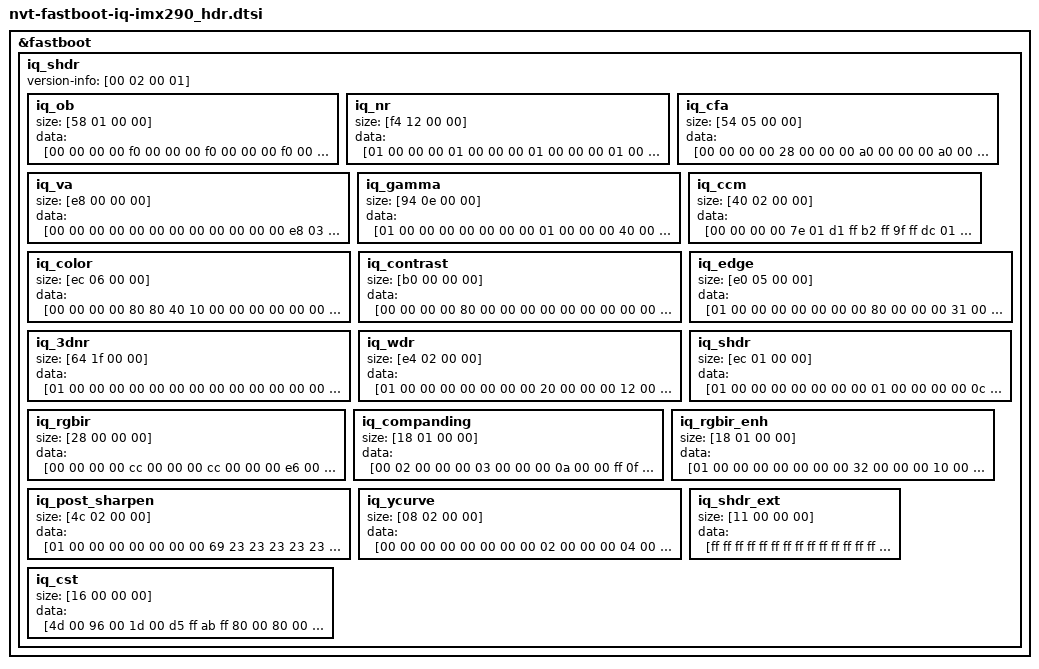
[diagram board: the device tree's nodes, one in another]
/*
 * Novatek Ltd. NVT9856x ISP part of dts
 */

&fastboot {
	iq_shdr {
		version-info = [00 02 00 01];
		iq_ob {
			size = [58 01 00 00];
			data = [00 00 00 00 f0 00 00 00 f0 00 00 00 f0 00 00 00 f0 00 00 00 f0 00 00 00 f0 00 00 00 f0 00 00 00 f0 00 00 00 f0 00 00 00 f0 00 00 00 f0 00 00 00 f0 00 00 00 f0 00 00 00 f0 00 00 00 f0 00 00 00 f0 00 00 00 f0 00 00 00 f0 00 00 00 f0 00 00 00 f0 00 00 00 f0 00 00 00 f0 00 00 00 f0 00 00 00 f0 00 00 00 f0 00 00 00 f0 00 00 00 f0 00 00 00 f0 00 00 00 f0 00 00 00 f0 00 00 00 f0 00 00 00 f0 00 00 00 f0 00 00 00 f0 00 00 00 f0 00 00 00 f0 00 00 00 f0 00 00 00 f0 00 00 00 f0 00 00 00 f0 00 00 00 f0 00 00 00 f0 00 00 00 f0 00 00 00 f0 00 00 00 f0 00 00 00 f0 00 00 00 f0 00 00 00 f0 00 00 00 f0 00 00 00 f0 00 00 00 f0 00 00 00 f0 00 00 00 f0 00 00 00 f0 00 00 00 f0 00 00 00 f0 00 00 00 f0 00 00 00 f0 00 00 00 f0 00 00 00 f0 00 00 00 f0 00 00 00 f0 00 00 00 f0 00 00 00 f0 00 00 00 f0 00 00 00 f0 00 00 00 f0 00 00 00 f0 00 00 00 f0 00 00 00 f0 00 00 00 f0 00 00 00 f0 00 00 00 f0 00 00 00 f0 00 00 00 f0 00 00 00 f0 00 00 00 f0 00 00 00 f0 00 00 00 f0 00 00 00 f0 00 00 00 f0 00 00 00 f0 00 00 00 f0 00 00 00 f0 00 00 00 f0 00 00 00];
		};
		iq_nr {
			size = [f4 12 00 00];
			data = [01 00 00 00 01 00 00 00 01 00 00 00 01 00 00 00 01 00 00 00 00 00 00 00 00 01 ff 00 00 00 00 00 00 00 00 00 ff 0f 00 00 ff 0f 00 00 ff 0f 00 00 ff 0f 00 00 ff 0f 00 00 ff 0f 00 00 ff 0f 00 00 ff 0f 00 00 ff 0f 00 00 ff 0f 00 00 00 01 80 00 00 00 00 00 00 00 00 00 00 00 00 00 00 00 00 00 00 00 00 00 00 00 00 00 00 00 00 00 00 00 00 00 00 00 00 00 00 00 00 00 00 00 00 00 00 00 00 00 00 00 00 00 00 00 00 00 00 00 00 00 00 00 00 00 00 00 00 00 00 00 00 00 00 00 00 00 00 00 00 00 00 00 00 00 00 00 00 00 00 00 00 00 00 00 00 00 00 00 00 00 00 00 00 00 00 00 00 00 00 00 00 00 00 00 00 00 00 00 00 00 00 00 00 00 00 00 00 00 00 00 00 00 00 00 00 00 00 00 00 00 00 00 00 00 00 00 00 00 00 00 00 00 00 00 00 00 00 00 00 00 00 00 00 00 00 00 00 00 00 00 00 00 00 00 00 00 00 00 00 00 00 00 00 00 00 00 00 00 00 00 00 00 80 00 00 00 00 00 00 00 00 00 00 00 00 00 00 00 00 00 00 00 00 00 00 00 00 00 00 00 02 00 00 00 02 00 00 00 00 01 ff 00 00 00 00 00 00 00 00 00 20 00 00 00 6c 07 00 00 3f 0c 00 00 ff 0f 00 00 ff 0f 00 00 20 00 00 00 6c 07 00 00 3f 0c 00 00 ff 0f 00 00 ff 0f 00 00 02 00 80 00 00 00 00 00 00 00 00 00 00 00 00 00 00 00 00 00 00 00 00 00 00 00 00 00 00 00 00 00 00 00 00 00 00 00 00 00 00 00 00 00 00 00 00 00 00 00 00 00 00 00 00 00 00 00 00 00 00 00 00 00 00 00 00 00 00 00 00 00 00 00 00 00 00 00 00 00 00 00 00 00 00 00 00 00 00 00 00 00 00 00 00 00 00 00 00 00 00 00 00 00 00 00 00 00 00 00 00 00 00 00 00 00 00 00 00 00 00 00 00 00 00 00 00 00 00 00 00 00 00 00 00 00 00 00 00 00 00 00 00 00 00 00 00 00 00 00 00 00 00 00 00 00 00 00 00 00 00 00 00 00 00 00 00 00 00 00 00 00 00 00 00 00 00 00 00 00 00 00 00 00 00 00 00 00 00 00 00 00 20 00 00 00 40 00 00 00 10 00 00 00 10 00 00 00 10 00 00 00 10 00 00 00 00 00 00 00 00 00 00 00 00 00 00 00 00 00 00 00 00 01 ff 00 00 00 00 00 00 00 00 00 20 00 00 00 6c 07 00 00 3f 0c 00 00 ff 0f 00 00 ff 0f 00 00 20 00 00 00 6c 07 00 00 3f 0c 00 00 ff 0f 00 00 ff 0f 00 00 02 00 80 00 00 00 00 00 00 00 00 00 00 00 00 00 01 00 00 00 01 00 00 00 01 00 00 00 00 00 00 00 01 00 00 00 01 00 00 00 02 00 00 00 02 00 00 00 02 00 00 00 02 00 00 00 03 00 00 00 03 00 00 00 03 00 00 00 03 00 00 00 03 00 00 00 04 00 00 00 04 00 00 00 04 00 00 00 04 00 00 00 04 00 00 00 00 00 00 00 01 00 00 00 02 00 00 00 03 00 00 00 03 00 00 00 04 00 00 00 00 00 00 00 01 00 00 00 01 00 00 00 02 00 00 00 02 00 00 00 02 00 00 00 02 00 00 00 03 00 00 00 03 00 00 00 03 00 00 00 03 00 00 00 03 00 00 00 04 00 00 00 04 00 00 00 04 00 00 00 04 00 00 00 04 00 00 00 00 00 00 00 20 00 00 00 40 00 00 00 10 00 00 00 10 00 00 00 10 00 00 00 10 00 00 00 00 00 00 00 00 00 00 00 00 00 00 00 00 00 00 00 00 01 ff 00 00 00 00 00 00 00 00 00 20 00 00 00 bb 06 00 00 1b 0b 00 00 ff 0f 00 00 ff 0f 00 00 20 00 00 00 bb 06 00 00 1b 0b 00 00 ff 0f 00 00 ff 0f 00 00 02 00 80 00 00 00 00 00 01 00 00 00 01 00 00 00 02 00 00 00 02 00 00 00 03 00 00 00 00 00 00 00 02 00 00 00 03 00 00 00 04 00 00 00 04 00 00 00 05 00 00 00 05 00 00 00 06 00 00 00 06 00 00 00 07 00 00 00 07 00 00 00 07 00 00 00 08 00 00 00 08 00 00 00 08 00 00 00 09 00 00 00 09 00 00 00 00 00 00 00 03 00 00 00 04 00 00 00 06 00 00 00 07 00 00 00 09 00 00 00 00 00 00 00 02 00 00 00 03 00 00 00 04 00 00 00 04 00 00 00 05 00 00 00 05 00 00 00 06 00 00 00 06 00 00 00 07 00 00 00 07 00 00 00 07 00 00 00 08 00 00 00 08 00 00 00 08 00 00 00 09 00 00 00 09 00 00 00 00 00 00 00 20 00 00 00 40 00 00 00 10 00 00 00 10 00 00 00 10 00 00 00 10 00 00 00 00 00 00 00 00 00 00 00 00 00 00 00 00 00 00 00 00 01 ff 00 00 00 00 00 00 00 00 00 20 00 00 00 44 06 00 00 57 0a 00 00 fe 0e 00 00 ff 0f 00 00 20 00 00 00 44 06 00 00 57 0a 00 00 fe 0e 00 00 ff 0f 00 00 02 00 80 00 00 00 00 00 01 00 00 00 02 00 00 00 03 00 00 00 03 00 00 00 04 00 00 00 00 00 00 00 03 00 00 00 04 00 00 00 05 00 00 00 06 00 00 00 07 00 00 00 07 00 00 00 08 00 00 00 09 00 00 00 09 00 00 00 0a 00 00 00 0a 00 00 00 0b 00 00 00 0b 00 00 00 0b 00 00 00 0c 00 00 00 0c 00 00 00 00 00 00 00 05 00 00 00 07 00 00 00 09 00 00 00 0a 00 00 00 0e 00 00 00 00 00 00 00 03 00 00 00 04 00 00 00 05 00 00 00 06 00 00 00 07 00 00 00 07 00 00 00 08 00 00 00 09 00 00 00 09 00 00 00 0a 00 00 00 0a 00 00 00 0b 00 00 00 0b 00 00 00 0b 00 00 00 0c 00 00 00 0c 00 00 00 00 00 00 00 20 00 00 00 40 00 00 00 10 00 00 00 10 00 00 00 10 00 00 00 10 00 00 00 00 00 00 00 02 00 00 00 00 00 00 00 00 00 00 00 00 01 ff 00 00 00 00 00 00 00 00 00 20 00 00 00 cd 05 00 00 92 09 00 00 e1 0d 00 00 ff 0f 00 00 20 00 00 00 cd 05 00 00 92 09 00 00 e1 0d 00 00 ff 0f 00 00 06 00 80 00 00 00 00 00 02 00 00 00 03 00 00 00 04 00 00 00 04 00 00 00 06 00 00 00 00 00 00 00 04 00 00 00 05 00 00 00 06 00 00 00 08 00 00 00 08 00 00 00 09 00 00 00 0a 00 00 00 0b 00 00 00 0c 00 00 00 0c 00 00 00 0d 00 00 00 0d 00 00 00 0e 00 00 00 0e 00 00 00 0f 00 00 00 10 00 00 00 00 00 00 00 07 00 00 00 09 00 00 00 0c 00 00 00 0e 00 00 00 13 00 00 00 00 00 00 00 04 00 00 00 05 00 00 00 06 00 00 00 08 00 00 00 08 00 00 00 09 00 00 00 0a 00 00 00 0b 00 00 00 0c 00 00 00 0c 00 00 00 0d 00 00 00 0d 00 00 00 0e 00 00 00 0e 00 00 00 0f 00 00 00 10 00 00 00 00 00 00 00 20 00 00 00 40 00 00 00 10 00 00 00 10 00 00 00 10 00 00 00 10 00 00 00 00 00 00 00 04 00 00 00 00 00 00 00 00 00 00 00 00 01 ff 00 00 00 00 00 00 00 00 00 20 00 00 00 56 05 00 00 ce 08 00 00 c4 0c 00 00 ff 0f 00 00 20 00 00 00 56 05 00 00 ce 08 00 00 c4 0c 00 00 ff 0f 00 00 08 00 80 00 00 00 00 00 03 00 00 00 05 00 00 00 06 00 00 00 07 00 00 00 0a 00 00 00 00 00 00 00 06 00 00 00 08 00 00 00 0a 00 00 00 0c 00 00 00 0d 00 00 00 0e 00 00 00 0f 00 00 00 10 00 00 00 12 00 00 00 12 00 00 00 13 00 00 00 14 00 00 00 15 00 00 00 16 00 00 00 17 00 00 00 18 00 00 00 00 00 00 00 0b 00 00 00 10 00 00 00 13 00 00 00 16 00 00 00 20 00 00 00 00 00 00 00 06 00 00 00 08 00 00 00 0a 00 00 00 0c 00 00 00 0d 00 00 00 0e 00 00 00 0f 00 00 00 10 00 00 00 12 00 00 00 12 00 00 00 13 00 00 00 14 00 00 00 15 00 00 00 16 00 00 00 17 00 00 00 18 00 00 00 00 00 00 00 20 00 00 00 40 00 00 00 10 00 00 00 10 00 00 00 10 00 00 00 10 00 00 00 00 00 00 00 06 00 00 00 00 00 00 00 00 00 00 00 00 01 ff 00 00 00 00 00 00 00 00 00 20 00 00 00 df 04 00 00 0a 08 00 00 a8 0b 00 00 ff 0f 00 00 20 00 00 00 df 04 00 00 0a 08 00 00 a8 0b 00 00 ff 0f 00 00 0f 00 80 00 00 00 00 00 05 00 00 00 07 00 00 00 09 00 00 00 0a 00 00 00 0e 00 00 00 00 00 00 00 09 00 00 00 0d 00 00 00 0f 00 00 00 12 00 00 00 14 00 00 00 16 00 00 00 18 00 00 00 1a 00 00 00 1b 00 00 00 1d 00 00 00 1e 00 00 00 1f 00 00 00 21 00 00 00 22 00 00 00 23 00 00 00 24 00 00 00 00 00 00 00 0f 00 00 00 16 00 00 00 1b 00 00 00 1f 00 00 00 2c 00 00 00 00 00 00 00 09 00 00 00 0d 00 00 00 0f 00 00 00 12 00 00 00 14 00 00 00 16 00 00 00 18 00 00 00 1a 00 00 00 1b 00 00 00 1d 00 00 00 1e 00 00 00 1f 00 00 00 21 00 00 00 22 00 00 00 23 00 00 00 24 00 00 00 08 00 00 00 20 00 00 00 40 00 00 00 10 00 00 00 10 00 00 00 10 00 00 00 10 00 00 00 00 00 00 00 08 00 00 00 01 00 00 00 01 00 00 00 00 01 ff 00 00 00 00 00 00 00 00 00 20 00 00 00 68 04 00 00 45 07 00 00 8a 0a 00 00 ff 0f 00 00 20 00 00 00 68 04 00 00 45 07 00 00 8a 0a 00 00 ff 0f 00 00 1e 00 80 00 00 00 00 00 07 00 00 00 0b 00 00 00 0d 00 00 00 0f 00 00 00 16 00 00 00 00 00 00 00 16 00 00 00 1f 00 00 00 26 00 00 00 2c 00 00 00 31 00 00 00 35 00 00 00 3a 00 00 00 3e 00 00 00 42 00 00 00 45 00 00 00 48 00 00 00 4c 00 00 00 4f 00 00 00 52 00 00 00 55 00 00 00 58 00 00 00 00 00 00 00 14 00 00 00 1d 00 00 00 24 00 00 00 29 00 00 00 3b 00 00 00 00 00 00 00 16 00 00 00 1f 00 00 00 26 00 00 00 2c 00 00 00 31 00 00 00 35 00 00 00 3a 00 00 00 3e 00 00 00 42 00 00 00 45 00 00 00 48 00 00 00 4c 00 00 00 4f 00 00 00 52 00 00 00 55 00 00 00 58 00 00 00 0f 00 00 00 20 00 00 00 40 00 00 00 10 00 00 00 14 00 00 00 10 00 00 00 14 00 00 00 04 00 00 00 10 00 00 00 01 00 00 00 02 00 00 00 00 01 ff 00 00 00 00 00 00 00 00 00 20 00 00 00 68 04 00 00 45 07 00 00 8a 0a 00 00 ff 0f 00 00 20 00 00 00 68 04 00 00 45 07 00 00 8a 0a 00 00 ff 0f 00 00 3c 00 80 00 00 00 00 00 08 00 00 00 0c 00 00 00 0e 00 00 00 11 00 00 00 18 00 00 00 00 00 00 00 26 00 00 00 36 00 00 00 42 00 00 00 4c 00 00 00 55 00 00 00 5e 00 00 00 65 00 00 00 6c 00 00 00 73 00 00 00 79 00 00 00 7f 00 00 00 85 00 00 00 8a 00 00 00 8f 00 00 00 94 00 00 00 99 00 00 00 00 00 00 00 19 00 00 00 24 00 00 00 2c 00 00 00 33 00 00 00 48 00 00 00 00 00 00 00 26 00 00 00 36 00 00 00 42 00 00 00 4c 00 00 00 55 00 00 00 5e 00 00 00 65 00 00 00 6c 00 00 00 73 00 00 00 79 00 00 00 7f 00 00 00 85 00 00 00 8a 00 00 00 8f 00 00 00 94 00 00 00 99 00 00 00 0f 00 00 00 20 00 00 00 40 00 00 00 14 00 00 00 18 00 00 00 14 00 00 00 18 00 00 00 04 00 00 00 12 00 00 00 01 00 00 00 02 00 00 00 00 01 ff 00 00 00 00 00 00 00 00 00 20 00 00 00 68 04 00 00 45 07 00 00 8a 0a 00 00 ff 0f 00 00 20 00 00 00 68 04 00 00 45 07 00 00 8a 0a 00 00 ff 0f 00 00 5a 00 80 00 00 00 00 00 0b 00 00 00 10 00 00 00 13 00 00 00 16 00 00 00 20 00 00 00 00 00 00 00 33 00 00 00 48 00 00 00 58 00 00 00 66 00 00 00 72 00 00 00 7d 00 00 00 87 00 00 00 90 00 00 00 99 00 00 00 a1 00 00 00 a9 00 00 00 b1 00 00 00 b8 00 00 00 bf 00 00 00 c6 00 00 00 cc 00 00 00 00 00 00 00 21 00 00 00 2f 00 00 00 3a 00 00 00 43 00 00 00 5e 00 00 00 00 00 00 00 33 00 00 00 48 00 00 00 58 00 00 00 66 00 00 00 72 00 00 00 7d 00 00 00 87 00 00 00 90 00 00 00 99 00 00 00 a1 00 00 00 a9 00 00 00 b1 00 00 00 b8 00 00 00 bf 00 00 00 c6 00 00 00 cc 00 00 00 0f 00 00 00 20 00 00 00 40 00 00 00 18 00 00 00 1c 00 00 00 18 00 00 00 1c 00 00 00 06 00 00 00 14 00 00 00 01 00 00 00 02 00 00 00 00 01 ff 00 00 00 00 00 00 00 00 00 20 00 00 00 68 04 00 00 45 07 00 00 8a 0a 00 00 ff 0f 00 00 20 00 00 00 68 04 00 00 45 07 00 00 8a 0a 00 00 ff 0f 00 00 5a 00 80 00 00 00 00 00 0d 00 00 00 13 00 00 00 17 00 00 00 1b 00 00 00 26 00 00 00 00 00 00 00 15 00 00 00 1d 00 00 00 24 00 00 00 2a 00 00 00 2f 00 00 00 33 00 00 00 38 00 00 00 3b 00 00 00 3f 00 00 00 43 00 00 00 46 00 00 00 49 00 00 00 4c 00 00 00 4f 00 00 00 52 00 00 00 54 00 00 00 00 00 00 00 28 00 00 00 39 00 00 00 46 00 00 00 51 00 00 00 72 00 00 00 00 00 00 00 40 00 00 00 5a 00 00 00 6e 00 00 00 80 00 00 00 8f 00 00 00 9c 00 00 00 a9 00 00 00 b5 00 00 00 c0 00 00 00 ca 00 00 00 d4 00 00 00 dd 00 00 00 e6 00 00 00 ef 00 00 00 f7 00 00 00 00 01 00 00 0f 00 00 00 20 00 00 00 40 00 00 00 1c 00 00 00 20 00 00 00 1c 00 00 00 20 00 00 00 0a 00 00 00 18 00 00 00 01 00 00 00 02 00 00 00 00 01 ff 00 00 00 00 00 00 00 00 00 20 00 00 00 68 04 00 00 45 07 00 00 8a 0a 00 00 ff 0f 00 00 20 00 00 00 68 04 00 00 45 07 00 00 8a 0a 00 00 ff 0f 00 00 5a 00 80 00 00 00 00 00 0d 00 00 00 13 00 00 00 17 00 00 00 1b 00 00 00 26 00 00 00 00 00 00 00 15 00 00 00 1d 00 00 00 24 00 00 00 2a 00 00 00 2f 00 00 00 33 00 00 00 38 00 00 00 3b 00 00 00 3f 00 00 00 43 00 00 00 46 00 00 00 49 00 00 00 4c 00 00 00 4f 00 00 00 52 00 00 00 54 00 00 00 00 00 00 00 28 00 00 00 39 00 00 00 46 00 00 00 51 00 00 00 72 00 00 00 00 00 00 00 40 00 00 00 5a 00 00 00 6e 00 00 00 80 00 00 00 8f 00 00 00 9c 00 00 00 a9 00 00 00 b5 00 00 00 c0 00 00 00 ca 00 00 00 d4 00 00 00 dd 00 00 00 e6 00 00 00 ef 00 00 00 f7 00 00 00 00 01 00 00 0f 00 00 00 20 00 00 00 40 00 00 00 1c 00 00 00 20 00 00 00 1c 00 00 00 20 00 00 00 0a 00 00 00 18 00 00 00 01 00 00 00 02 00 00 00 00 01 ff 00 00 00 00 00 00 00 00 00 20 00 00 00 68 04 00 00 45 07 00 00 8a 0a 00 00 ff 0f 00 00 20 00 00 00 68 04 00 00 45 07 00 00 8a 0a 00 00 ff 0f 00 00 5a 00 80 00 00 00 00 00 0d 00 00 00 13 00 00 00 17 00 00 00 1b 00 00 00 26 00 00 00 00 00 00 00 15 00 00 00 1d 00 00 00 24 00 00 00 2a 00 00 00 2f 00 00 00 33 00 00 00 38 00 00 00 3b 00 00 00 3f 00 00 00 43 00 00 00 46 00 00 00 49 00 00 00 4c 00 00 00 4f 00 00 00 52 00 00 00 54 00 00 00 00 00 00 00 28 00 00 00 39 00 00 00 46 00 00 00 51 00 00 00 72 00 00 00 00 00 00 00 40 00 00 00 5a 00 00 00 6e 00 00 00 80 00 00 00 8f 00 00 00 9c 00 00 00 a9 00 00 00 b5 00 00 00 c0 00 00 00 ca 00 00 00 d4 00 00 00 dd 00 00 00 e6 00 00 00 ef 00 00 00 f7 00 00 00 00 01 00 00 0f 00 00 00 20 00 00 00 40 00 00 00 1c 00 00 00 20 00 00 00 1c 00 00 00 20 00 00 00 0a 00 00 00 18 00 00 00 01 00 00 00 02 00 00 00 00 01 ff 00 00 00 00 00 00 00 00 00 20 00 00 00 68 04 00 00 45 07 00 00 8a 0a 00 00 ff 0f 00 00 20 00 00 00 68 04 00 00 45 07 00 00 8a 0a 00 00 ff 0f 00 00 5a 00 80 00 00 00 00 00 0d 00 00 00 13 00 00 00 17 00 00 00 1b 00 00 00 26 00 00 00 00 00 00 00 15 00 00 00 1d 00 00 00 24 00 00 00 2a 00 00 00 2f 00 00 00 33 00 00 00 38 00 00 00 3b 00 00 00 3f 00 00 00 43 00 00 00 46 00 00 00 49 00 00 00 4c 00 00 00 4f 00 00 00 52 00 00 00 54 00 00 00 00 00 00 00 28 00 00 00 39 00 00 00 46 00 00 00 51 00 00 00 72 00 00 00 00 00 00 00 40 00 00 00 5a 00 00 00 6e 00 00 00 80 00 00 00 8f 00 00 00 9c 00 00 00 a9 00 00 00 b5 00 00 00 c0 00 00 00 ca 00 00 00 d4 00 00 00 dd 00 00 00 e6 00 00 00 ef 00 00 00 f7 00 00 00 00 01 00 00 0f 00 00 00 20 00 00 00 40 00 00 00 1c 00 00 00 20 00 00 00 1c 00 00 00 20 00 00 00 0a 00 00 00 18 00 00 00 01 00 00 00 02 00 00 00 00 01 ff 00 00 00 00 00 00 00 00 00 20 00 00 00 68 04 00 00 45 07 00 00 8a 0a 00 00 ff 0f 00 00 20 00 00 00 68 04 00 00 45 07 00 00 8a 0a 00 00 ff 0f 00 00 5a 00 80 00 00 00 00 00 0d 00 00 00 13 00 00 00 17 00 00 00 1b 00 00 00 26 00 00 00 00 00 00 00 15 00 00 00 1d 00 00 00 24 00 00 00 2a 00 00 00 2f 00 00 00 33 00 00 00 38 00 00 00 3b 00 00 00 3f 00 00 00 43 00 00 00 46 00 00 00 49 00 00 00 4c 00 00 00 4f 00 00 00 52 00 00 00 54 00 00 00 00 00 00 00 28 00 00 00 39 00 00 00 46 00 00 00 51 00 00 00 72 00 00 00 00 00 00 00 40 00 00 00 5a 00 00 00 6e 00 00 00 80 00 00 00 8f 00 00 00 9c 00 00 00 a9 00 00 00 b5 00 00 00 c0 00 00 00 ca 00 00 00 d4 00 00 00 dd 00 00 00 e6 00 00 00 ef 00 00 00 f7 00 00 00 00 01 00 00 0f 00 00 00 20 00 00 00 40 00 00 00 1c 00 00 00 20 00 00 00 1c 00 00 00 20 00 00 00 0a 00 00 00 18 00 00 00 01 00 00 00 02 00 00 00 00 01 ff 00 00 00 00 00 00 00 00 00 20 00 00 00 68 04 00 00 45 07 00 00 8a 0a 00 00 ff 0f 00 00 20 00 00 00 68 04 00 00 45 07 00 00 8a 0a 00 00 ff 0f 00 00 5a 00 80 00 00 00 00 00 0d 00 00 00 13 00 00 00 17 00 00 00 1b 00 00 00 26 00 00 00 00 00 00 00 15 00 00 00 1d 00 00 00 24 00 00 00 2a 00 00 00 2f 00 00 00 33 00 00 00 38 00 00 00 3b 00 00 00 3f 00 00 00 43 00 00 00 46 00 00 00 49 00 00 00 4c 00 00 00 4f 00 00 00 52 00 00 00 54 00 00 00 00 00 00 00 28 00 00 00 39 00 00 00 46 00 00 00 51 00 00 00 72 00 00 00 00 00 00 00 40 00 00 00 5a 00 00 00 6e 00 00 00 80 00 00 00 8f 00 00 00 9c 00 00 00 a9 00 00 00 b5 00 00 00 c0 00 00 00 ca 00 00 00 d4 00 00 00 dd 00 00 00 e6 00 00 00 ef 00 00 00 f7 00 00 00 00 01 00 00 0f 00 00 00 20 00 00 00 40 00 00 00 1c 00 00 00 20 00 00 00 1c 00 00 00 20 00 00 00 0a 00 00 00 18 00 00 00 01 00 00 00 02 00 00 00];
		};
		iq_cfa {
			size = [54 05 00 00];
			data = [00 00 00 00 28 00 00 00 a0 00 00 00 a0 00 00 00 40 00 00 00 0f 00 00 00 0f 00 00 00 07 00 00 00 04 00 00 00 03 00 00 00 02 00 00 00 02 00 00 00 01 00 00 00 01 00 00 00 01 00 00 00 01 00 00 00 00 00 00 00 00 00 00 00 00 00 00 00 00 00 00 00 00 00 00 00 28 00 00 00 a0 00 00 00 a0 00 00 00 40 00 00 00 0f 00 00 00 0f 00 00 00 07 00 00 00 04 00 00 00 03 00 00 00 02 00 00 00 02 00 00 00 01 00 00 00 01 00 00 00 01 00 00 00 01 00 00 00 00 00 00 00 00 00 00 00 00 00 00 00 00 00 00 00 00 00 00 00 28 00 00 00 a0 00 00 00 a0 00 00 00 40 00 00 00 0f 00 00 00 0f 00 00 00 07 00 00 00 04 00 00 00 03 00 00 00 02 00 00 00 02 00 00 00 01 00 00 00 01 00 00 00 01 00 00 00 01 00 00 00 00 00 00 00 00 00 00 00 00 00 00 00 00 00 00 00 00 00 00 00 28 00 00 00 a0 00 00 00 a0 00 00 00 40 00 00 00 0f 00 00 00 0f 00 00 00 07 00 00 00 04 00 00 00 03 00 00 00 02 00 00 00 02 00 00 00 01 00 00 00 01 00 00 00 01 00 00 00 01 00 00 00 00 00 00 00 00 00 00 00 00 00 00 00 00 00 00 00 00 00 00 00 28 00 00 00 a0 00 00 00 a0 00 00 00 40 00 00 00 0f 00 00 00 0f 00 00 00 07 00 00 00 04 00 00 00 03 00 00 00 02 00 00 00 02 00 00 00 01 00 00 00 01 00 00 00 01 00 00 00 01 00 00 00 00 00 00 00 00 00 00 00 00 00 00 00 00 00 00 00 00 00 00 00 28 00 00 00 a0 00 00 00 a0 00 00 00 40 00 00 00 0f 00 00 00 0f 00 00 00 07 00 00 00 04 00 00 00 03 00 00 00 02 00 00 00 02 00 00 00 01 00 00 00 01 00 00 00 01 00 00 00 01 00 00 00 00 00 00 00 00 00 00 00 00 00 00 00 00 00 00 00 00 00 00 00 28 00 00 00 a0 00 00 00 a0 00 00 00 40 00 00 00 0f 00 00 00 0f 00 00 00 07 00 00 00 04 00 00 00 03 00 00 00 02 00 00 00 02 00 00 00 01 00 00 00 01 00 00 00 01 00 00 00 01 00 00 00 00 00 00 00 00 00 00 00 00 00 00 00 00 00 00 00 00 00 00 00 28 00 00 00 a0 00 00 00 a0 00 00 00 30 00 00 00 0f 00 00 00 0f 00 00 00 07 00 00 00 04 00 00 00 03 00 00 00 02 00 00 00 02 00 00 00 01 00 00 00 01 00 00 00 01 00 00 00 01 00 00 00 00 00 00 00 00 00 00 00 00 00 00 00 00 00 00 00 00 00 00 00 28 00 00 00 a0 00 00 00 a0 00 00 00 10 00 00 00 0f 00 00 00 0f 00 00 00 07 00 00 00 04 00 00 00 03 00 00 00 02 00 00 00 02 00 00 00 01 00 00 00 01 00 00 00 01 00 00 00 01 00 00 00 00 00 00 00 00 00 00 00 00 00 00 00 00 00 00 00 00 00 00 00 28 00 00 00 a0 00 00 00 a0 00 00 00 10 00 00 00 0f 00 00 00 0f 00 00 00 07 00 00 00 04 00 00 00 03 00 00 00 02 00 00 00 02 00 00 00 01 00 00 00 01 00 00 00 01 00 00 00 01 00 00 00 00 00 00 00 00 00 00 00 00 00 00 00 00 00 00 00 00 00 00 00 28 00 00 00 a0 00 00 00 a0 00 00 00 10 00 00 00 0f 00 00 00 0f 00 00 00 07 00 00 00 04 00 00 00 03 00 00 00 02 00 00 00 02 00 00 00 01 00 00 00 01 00 00 00 01 00 00 00 01 00 00 00 00 00 00 00 00 00 00 00 00 00 00 00 00 00 00 00 00 00 00 00 28 00 00 00 a0 00 00 00 a0 00 00 00 10 00 00 00 0f 00 00 00 0f 00 00 00 07 00 00 00 04 00 00 00 03 00 00 00 02 00 00 00 02 00 00 00 01 00 00 00 01 00 00 00 01 00 00 00 01 00 00 00 00 00 00 00 00 00 00 00 00 00 00 00 00 00 00 00 00 00 00 00 28 00 00 00 a0 00 00 00 a0 00 00 00 10 00 00 00 0f 00 00 00 0f 00 00 00 07 00 00 00 04 00 00 00 03 00 00 00 02 00 00 00 02 00 00 00 01 00 00 00 01 00 00 00 01 00 00 00 01 00 00 00 00 00 00 00 00 00 00 00 00 00 00 00 00 00 00 00 00 00 00 00 28 00 00 00 a0 00 00 00 a0 00 00 00 10 00 00 00 0f 00 00 00 0f 00 00 00 07 00 00 00 04 00 00 00 03 00 00 00 02 00 00 00 02 00 00 00 01 00 00 00 01 00 00 00 01 00 00 00 01 00 00 00 00 00 00 00 00 00 00 00 00 00 00 00 00 00 00 00 00 00 00 00 28 00 00 00 a0 00 00 00 a0 00 00 00 10 00 00 00 0f 00 00 00 0f 00 00 00 07 00 00 00 04 00 00 00 03 00 00 00 02 00 00 00 02 00 00 00 01 00 00 00 01 00 00 00 01 00 00 00 01 00 00 00 00 00 00 00 00 00 00 00 00 00 00 00 00 00 00 00 00 00 00 00 28 00 00 00 a0 00 00 00 a0 00 00 00 10 00 00 00 0f 00 00 00 0f 00 00 00 07 00 00 00 04 00 00 00 03 00 00 00 02 00 00 00 02 00 00 00 01 00 00 00 01 00 00 00 01 00 00 00 01 00 00 00 00 00 00 00 00 00 00 00 00 00 00 00 00 00 00 00 00 00 00 00 28 00 00 00 a0 00 00 00 a0 00 00 00 10 00 00 00 0f 00 00 00 0f 00 00 00 07 00 00 00 04 00 00 00 03 00 00 00 02 00 00 00 02 00 00 00 01 00 00 00 01 00 00 00 01 00 00 00 01 00 00 00 00 00 00 00 00 00 00 00 00 00 00 00 00 00 00 00 00 00 00 00];
		};
		iq_va {
			size = [e8 00 00 00];
			data = [00 00 00 00 00 00 00 00 00 00 00 00 e8 03 00 00 e8 03 00 00 00 00 00 00 00 00 00 00 e8 03 00 00 e8 03 00 00 00 00 00 00 00 00 00 00 e8 03 00 00 e8 03 00 00 00 00 00 00 00 00 00 00 e8 03 00 00 e8 03 00 00 00 00 00 00 00 00 00 00 e8 03 00 00 e8 03 00 00 00 00 ff 00 02 02 00 ff 00 03 00 00 00 00 00 00 00 00 00 00 00 00 00 00 00 00 00 00 00 00 00 00 00 00 00 00 00 00 00 00 00 00 00 00 00 00 00 00 00 00 00 00 00 00 00 00 00 00 00 00 00 00 00 00 00 00 00 00 00 00 00 00 00 00 00 00 00 00 00 00 00 00 00 00 00 00 00 00 00 00 00 00 00 00 00 00 00 00 00 00 00 00 00 00 00 00 00 00 00 00 00 00 00 00 00 00 00 00 00 00 00 00 00 00 00 00 00 00 00 00 00 00 00 00 00 00 00 00 00 00 00 00 00 00 00 00 00 00];
		};
		iq_gamma {
			size = [94 0e 00 00];
			data = [01 00 00 00 00 00 00 00 01 00 00 00 40 00 00 00 40 00 00 00 40 00 00 00 40 00 00 00 40 00 00 00 40 00 00 00 40 00 00 00 40 00 00 00 40 00 00 00 40 00 00 00 40 00 00 00 40 00 00 00 40 00 00 00 40 00 00 00 40 00 00 00 40 00 00 00 40 00 00 00 00 00 00 00 08 00 00 00 10 00 00 00 18 00 00 00 1c 00 00 00 20 00 00 00 24 00 00 00 26 00 00 00 28 00 00 00 29 00 00 00 2a 00 00 00 2b 00 00 00 2c 00 00 00 2d 00 00 00 2e 00 00 00 2f 00 00 00 30 00 00 00 31 00 00 00 32 00 00 00 33 00 00 00 34 00 00 00 35 00 00 00 36 00 00 00 37 00 00 00 38 00 00 00 39 00 00 00 3a 00 00 00 3b 00 00 00 3c 00 00 00 3d 00 00 00 3e 00 00 00 3f 00 00 00 03 00 00 00 03 00 00 00 03 00 00 00 02 00 00 00 02 00 00 00 02 00 00 00 01 00 00 00 01 00 00 00 00 00 00 00 00 00 00 00 00 00 00 00 00 00 00 00 00 00 00 00 00 00 00 00 00 00 00 00 00 00 00 00 00 00 00 00 00 00 00 00 00 00 00 00 00 00 00 00 00 00 00 00 00 00 00 00 00 00 00 00 00 00 00 00 00 00 00 00 00 00 00 00 00 00 00 00 00 00 00 00 00 00 00 00 00 00 00 00 00 00 00 00 00 00 00 00 00 00 00 00 10 00 00 00 20 00 00 00 30 00 00 00 40 00 00 00 50 00 00 00 60 00 00 00 70 00 00 00 80 00 00 00 90 00 00 00 a0 00 00 00 b0 00 00 00 c0 00 00 00 d0 00 00 00 e0 00 00 00 f0 00 00 00 00 01 00 00 10 01 00 00 20 01 00 00 30 01 00 00 40 01 00 00 50 01 00 00 60 01 00 00 70 01 00 00 80 01 00 00 a0 01 00 00 c0 01 00 00 e0 01 00 00 00 02 00 00 20 02 00 00 40 02 00 00 60 02 00 00 80 02 00 00 a0 02 00 00 c0 02 00 00 e0 02 00 00 00 03 00 00 40 03 00 00 80 03 00 00 c0 03 00 00 00 04 00 00 80 04 00 00 00 05 00 00 80 05 00 00 00 06 00 00 80 06 00 00 00 07 00 00 80 07 00 00 00 08 00 00 80 08 00 00 00 09 00 00 80 09 00 00 00 0a 00 00 80 0a 00 00 00 0b 00 00 80 0b 00 00 00 0c 00 00 80 0c 00 00 00 0d 00 00 80 0d 00 00 00 0e 00 00 80 0e 00 00 00 0f 00 00 80 0f 00 00 ff 0f 00 00 00 00 00 00 04 00 00 00 08 00 00 00 0c 00 00 00 10 00 00 00 14 00 00 00 18 00 00 00 1a 00 00 00 1c 00 00 00 1d 00 00 00 1e 00 00 00 1f 00 00 00 20 00 00 00 21 00 00 00 22 00 00 00 23 00 00 00 24 00 00 00 25 00 00 00 26 00 00 00 27 00 00 00 28 00 00 00 29 00 00 00 2a 00 00 00 2b 00 00 00 2c 00 00 00 2d 00 00 00 2e 00 00 00 2f 00 00 00 30 00 00 00 34 00 00 00 38 00 00 00 3c 00 00 00 02 00 00 00 02 00 00 00 02 00 00 00 02 00 00 00 02 00 00 00 02 00 00 00 01 00 00 00 01 00 00 00 00 00 00 00 00 00 00 00 00 00 00 00 00 00 00 00 00 00 00 00 00 00 00 00 00 00 00 00 00 00 00 00 00 00 00 00 00 00 00 00 00 00 00 00 00 00 00 00 00 00 00 00 00 00 00 00 00 00 00 00 00 00 00 00 00 00 00 00 00 00 00 00 00 00 00 00 00 00 00 00 02 00 00 00 02 00 00 00 02 00 00 00 02 00 00 00 05 00 00 00 00 00 00 00 00 00 00 00 e0 00 00 00 9e 01 00 00 43 02 00 00 d5 02 00 00 58 03 00 00 cf 03 00 00 39 04 00 00 9e 04 00 00 f8 04 00 00 4e 05 00 00 9f 05 00 00 ed 05 00 00 32 06 00 00 76 06 00 00 b6 06 00 00 f5 06 00 00 30 07 00 00 69 07 00 00 9f 07 00 00 d3 07 00 00 04 08 00 00 33 08 00 00 5f 08 00 00 89 08 00 00 de 08 00 00 2d 09 00 00 77 09 00 00 ba 09 00 00 3b 0a 00 00 af 0a 00 00 1a 0b 00 00 7d 0b 00 00 d8 0b 00 00 2d 0c 00 00 7d 0c 00 00 c8 0c 00 00 0e 0d 00 00 51 0d 00 00 91 0d 00 00 cd 0d 00 00 07 0e 00 00 3e 0e 00 00 73 0e 00 00 a6 0e 00 00 d7 0e 00 00 06 0f 00 00 33 0f 00 00 5f 0f 00 00 69 0f 00 00 74 0f 00 00 7e 0f 00 00 89 0f 00 00 93 0f 00 00 9d 0f 00 00 a7 0f 00 00 b2 0f 00 00 bc 0f 00 00 c6 0f 00 00 cf 0f 00 00 d9 0f 00 00 e3 0f 00 00 ec 0f 00 00 f6 0f 00 00 ff 0f 00 00 19 00 00 00 00 00 00 00 e0 00 00 00 9e 01 00 00 43 02 00 00 d5 02 00 00 58 03 00 00 cf 03 00 00 3b 04 00 00 9e 04 00 00 f1 04 00 00 40 05 00 00 88 05 00 00 cc 05 00 00 03 06 00 00 39 06 00 00 6d 06 00 00 a0 06 00 00 d0 06 00 00 ff 06 00 00 2c 07 00 00 57 07 00 00 81 07 00 00 a8 07 00 00 ce 07 00 00 f3 07 00 00 3c 08 00 00 82 08 00 00 c3 08 00 00 00 09 00 00 76 09 00 00 e3 09 00 00 4a 0a 00 00 ab 0a 00 00 06 0b 00 00 5e 0b 00 00 b1 0b 00 00 02 0c 00 00 4e 0c 00 00 99 0c 00 00 e2 0c 00 00 28 0d 00 00 6c 0d 00 00 ae 0d 00 00 ef 0d 00 00 2f 0e 00 00 6d 0e 00 00 aa 0e 00 00 e5 0e 00 00 20 0f 00 00 2d 0f 00 00 3c 0f 00 00 4a 0f 00 00 59 0f 00 00 67 0f 00 00 75 0f 00 00 83 0f 00 00 91 0f 00 00 9f 0f 00 00 ad 0f 00 00 ba 0f 00 00 c8 0f 00 00 d6 0f 00 00 e4 0f 00 00 f2 0f 00 00 ff 0f 00 00 32 00 00 00 00 00 00 00 e0 00 00 00 9e 01 00 00 43 02 00 00 d5 02 00 00 58 03 00 00 cf 03 00 00 3c 04 00 00 9e 04 00 00 ed 04 00 00 36 05 00 00 79 05 00 00 b6 05 00 00 e4 05 00 00 11 06 00 00 3d 06 00 00 68 06 00 00 91 06 00 00 b9 06 00 00 e0 06 00 00 05 07 00 00 29 07 00 00 4c 07 00 00 6e 07 00 00 8f 07 00 00 d0 07 00 00 0f 08 00 00 4b 08 00 00 84 08 00 00 f3 08 00 00 5b 09 00 00 bf 09 00 00 1f 0a 00 00 7b 0a 00 00 d4 0a 00 00 2a 0b 00 00 7e 0b 00 00 cf 0b 00 00 1f 0c 00 00 6d 0c 00 00 ba 0c 00 00 05 0d 00 00 4f 0d 00 00 98 0d 00 00 e0 0d 00 00 27 0e 00 00 6c 0e 00 00 b1 0e 00 00 f6 0e 00 00 06 0f 00 00 17 0f 00 00 28 0f 00 00 39 0f 00 00 4a 0f 00 00 5a 0f 00 00 6b 0f 00 00 7c 0f 00 00 8c 0f 00 00 9d 0f 00 00 ad 0f 00 00 be 0f 00 00 ce 0f 00 00 de 0f 00 00 ef 0f 00 00 ff 0f 00 00 4b 00 00 00 00 00 00 00 57 01 00 00 59 02 00 00 27 03 00 00 d4 03 00 00 68 04 00 00 e9 04 00 00 5e 05 00 00 c4 05 00 00 0f 06 00 00 52 06 00 00 8e 06 00 00 c3 06 00 00 e5 06 00 00 07 07 00 00 27 07 00 00 48 07 00 00 67 07 00 00 85 07 00 00 a3 07 00 00 c0 07 00 00 dc 07 00 00 f7 07 00 00 12 08 00 00 2c 08 00 00 60 08 00 00 92 08 00 00 c3 08 00 00 f2 08 00 00 4f 09 00 00 a7 09 00 00 fd 09 00 00 51 0a 00 00 a3 0a 00 00 f3 0a 00 00 41 0b 00 00 8f 0b 00 00 da 0b 00 00 26 0c 00 00 70 0c 00 00 b9 0c 00 00 02 0d 00 00 4a 0d 00 00 91 0d 00 00 d8 0d 00 00 1f 0e 00 00 65 0e 00 00 aa 0e 00 00 ef 0e 00 00 00 0f 00 00 11 0f 00 00 22 0f 00 00 34 0f 00 00 45 0f 00 00 56 0f 00 00 67 0f 00 00 78 0f 00 00 89 0f 00 00 9a 0f 00 00 ab 0f 00 00 bc 0f 00 00 cd 0f 00 00 dd 0f 00 00 ee 0f 00 00 ff 0f 00 00 64 00 00 00 00 00 00 00 d6 02 00 00 46 04 00 00 3e 05 00 00 fa 05 00 00 90 06 00 00 0e 07 00 00 7c 07 00 00 da 07 00 00 18 08 00 00 4e 08 00 00 7d 08 00 00 a5 08 00 00 b9 08 00 00 cd 08 00 00 e1 08 00 00 f5 08 00 00 08 09 00 00 1b 09 00 00 2e 09 00 00 41 09 00 00 53 09 00 00 65 09 00 00 77 09 00 00 89 09 00 00 ac 09 00 00 cf 09 00 00 f2 09 00 00 14 0a 00 00 58 0a 00 00 9a 0a 00 00 dc 0a 00 00 1e 0b 00 00 5f 0b 00 00 9f 0b 00 00 df 0b 00 00 1f 0c 00 00 5e 0c 00 00 9d 0c 00 00 dc 0c 00 00 1b 0d 00 00 59 0d 00 00 97 0d 00 00 d6 0d 00 00 14 0e 00 00 51 0e 00 00 8f 0e 00 00 cd 0e 00 00 0a 0f 00 00 1a 0f 00 00 29 0f 00 00 38 0f 00 00 48 0f 00 00 57 0f 00 00 66 0f 00 00 76 0f 00 00 85 0f 00 00 94 0f 00 00 a4 0f 00 00 b3 0f 00 00 c2 0f 00 00 d2 0f 00 00 e1 0f 00 00 f0 0f 00 00 ff 0f 00 00 00 00 00 00 25 00 00 00 49 00 00 00 6b 00 00 00 8b 00 00 00 a9 00 00 00 c6 00 00 00 e1 00 00 00 f1 00 00 00 01 01 00 00 11 01 00 00 21 01 00 00 30 01 00 00 3e 01 00 00 4d 01 00 00 5b 01 00 00 68 01 00 00 75 01 00 00 82 01 00 00 8f 01 00 00 9b 01 00 00 a6 01 00 00 b1 01 00 00 bc 01 00 00 c7 01 00 00 d1 01 00 00 db 01 00 00 e4 01 00 00 ed 01 00 00 f6 01 00 00 fe 01 00 00 06 02 00 00 0d 02 00 00 14 02 00 00 1b 02 00 00 22 02 00 00 29 02 00 00 30 02 00 00 36 02 00 00 3d 02 00 00 44 02 00 00 4b 02 00 00 52 02 00 00 59 02 00 00 5f 02 00 00 66 02 00 00 6d 02 00 00 73 02 00 00 7a 02 00 00 80 02 00 00 87 02 00 00 8d 02 00 00 93 02 00 00 9a 02 00 00 a0 02 00 00 a6 02 00 00 ac 02 00 00 b3 02 00 00 b9 02 00 00 bf 02 00 00 c5 02 00 00 cb 02 00 00 d1 02 00 00 d7 02 00 00 dd 02 00 00 e3 02 00 00 e8 02 00 00 ee 02 00 00 f4 02 00 00 fa 02 00 00 ff 02 00 00 04 03 00 00 09 03 00 00 0e 03 00 00 13 03 00 00 18 03 00 00 1d 03 00 00 21 03 00 00 26 03 00 00 2b 03 00 00 30 03 00 00 35 03 00 00 3a 03 00 00 3e 03 00 00 43 03 00 00 48 03 00 00 4d 03 00 00 51 03 00 00 56 03 00 00 5b 03 00 00 5f 03 00 00 64 03 00 00 68 03 00 00 6d 03 00 00 72 03 00 00 76 03 00 00 7b 03 00 00 7f 03 00 00 84 03 00 00 88 03 00 00 8c 03 00 00 91 03 00 00 95 03 00 00 99 03 00 00 9e 03 00 00 a2 03 00 00 a6 03 00 00 ab 03 00 00 af 03 00 00 b3 03 00 00 b7 03 00 00 bb 03 00 00 bf 03 00 00 c4 03 00 00 c8 03 00 00 cc 03 00 00 d0 03 00 00 d4 03 00 00 d8 03 00 00 dc 03 00 00 e0 03 00 00 e4 03 00 00 e8 03 00 00 eb 03 00 00 ef 03 00 00 f3 03 00 00 f7 03 00 00 fb 03 00 00 ff 03 00 00 06 00 00 00 00 00 00 00 25 00 00 00 49 00 00 00 6b 00 00 00 8b 00 00 00 a9 00 00 00 c6 00 00 00 e1 00 00 00 f1 00 00 00 01 01 00 00 11 01 00 00 21 01 00 00 30 01 00 00 3e 01 00 00 4d 01 00 00 5b 01 00 00 68 01 00 00 75 01 00 00 82 01 00 00 8f 01 00 00 9b 01 00 00 a6 01 00 00 b1 01 00 00 bc 01 00 00 c7 01 00 00 d1 01 00 00 db 01 00 00 e4 01 00 00 ed 01 00 00 f6 01 00 00 fe 01 00 00 06 02 00 00 0d 02 00 00 14 02 00 00 1b 02 00 00 22 02 00 00 29 02 00 00 30 02 00 00 36 02 00 00 3d 02 00 00 44 02 00 00 4b 02 00 00 52 02 00 00 59 02 00 00 5f 02 00 00 66 02 00 00 6d 02 00 00 73 02 00 00 7a 02 00 00 80 02 00 00 87 02 00 00 8d 02 00 00 93 02 00 00 9a 02 00 00 a0 02 00 00 a6 02 00 00 ac 02 00 00 b3 02 00 00 b9 02 00 00 bf 02 00 00 c5 02 00 00 cb 02 00 00 d1 02 00 00 d7 02 00 00 dd 02 00 00 e3 02 00 00 e8 02 00 00 ee 02 00 00 f4 02 00 00 fa 02 00 00 ff 02 00 00 04 03 00 00 09 03 00 00 0e 03 00 00 13 03 00 00 18 03 00 00 1d 03 00 00 21 03 00 00 26 03 00 00 2b 03 00 00 30 03 00 00 35 03 00 00 3a 03 00 00 3e 03 00 00 43 03 00 00 48 03 00 00 4d 03 00 00 51 03 00 00 56 03 00 00 5b 03 00 00 5f 03 00 00 64 03 00 00 68 03 00 00 6d 03 00 00 72 03 00 00 76 03 00 00 7b 03 00 00 7f 03 00 00 84 03 00 00 88 03 00 00 8c 03 00 00 91 03 00 00 95 03 00 00 99 03 00 00 9e 03 00 00 a2 03 00 00 a6 03 00 00 ab 03 00 00 af 03 00 00 b3 03 00 00 b7 03 00 00 bb 03 00 00 bf 03 00 00 c4 03 00 00 c8 03 00 00 cc 03 00 00 d0 03 00 00 d4 03 00 00 d8 03 00 00 dc 03 00 00 e0 03 00 00 e4 03 00 00 e8 03 00 00 eb 03 00 00 ef 03 00 00 f3 03 00 00 f7 03 00 00 fb 03 00 00 ff 03 00 00 04 00 00 00 00 00 00 00 25 00 00 00 49 00 00 00 6b 00 00 00 8b 00 00 00 a9 00 00 00 c6 00 00 00 e1 00 00 00 f1 00 00 00 01 01 00 00 11 01 00 00 21 01 00 00 30 01 00 00 3e 01 00 00 4d 01 00 00 5b 01 00 00 68 01 00 00 75 01 00 00 82 01 00 00 8f 01 00 00 9b 01 00 00 a6 01 00 00 b1 01 00 00 bc 01 00 00 c7 01 00 00 d1 01 00 00 db 01 00 00 e4 01 00 00 ed 01 00 00 f6 01 00 00 fe 01 00 00 06 02 00 00 0d 02 00 00 14 02 00 00 1b 02 00 00 22 02 00 00 29 02 00 00 30 02 00 00 36 02 00 00 3d 02 00 00 44 02 00 00 4b 02 00 00 52 02 00 00 59 02 00 00 5f 02 00 00 66 02 00 00 6d 02 00 00 73 02 00 00 7a 02 00 00 80 02 00 00 87 02 00 00 8d 02 00 00 93 02 00 00 9a 02 00 00 a0 02 00 00 a6 02 00 00 ac 02 00 00 b3 02 00 00 b9 02 00 00 bf 02 00 00 c5 02 00 00 cb 02 00 00 d1 02 00 00 d7 02 00 00 dd 02 00 00 e3 02 00 00 e8 02 00 00 ee 02 00 00 f4 02 00 00 fa 02 00 00 ff 02 00 00 04 03 00 00 09 03 00 00 0e 03 00 00 13 03 00 00 18 03 00 00 1d 03 00 00 21 03 00 00 26 03 00 00 2b 03 00 00 30 03 00 00 35 03 00 00 3a 03 00 00 3e 03 00 00 43 03 00 00 48 03 00 00 4d 03 00 00 51 03 00 00 56 03 00 00 5b 03 00 00 5f 03 00 00 64 03 00 00 68 03 00 00 6d 03 00 00 72 03 00 00 76 03 00 00 7b 03 00 00 7f 03 00 00 84 03 00 00 88 03 00 00 8c 03 00 00 91 03 00 00 95 03 00 00 99 03 00 00 9e 03 00 00 a2 03 00 00 a6 03 00 00 ab 03 00 00 af 03 00 00 b3 03 00 00 b7 03 00 00 bb 03 00 00 bf 03 00 00 c4 03 00 00 c8 03 00 00 cc 03 00 00 d0 03 00 00 d4 03 00 00 d8 03 00 00 dc 03 00 00 e0 03 00 00 e4 03 00 00 e8 03 00 00 eb 03 00 00 ef 03 00 00 f3 03 00 00 f7 03 00 00 fb 03 00 00 ff 03 00 00];
		};
		iq_ccm {
			size = [40 02 00 00];
			data = [00 00 00 00 7e 01 d1 ff b2 ff 9f ff dc 01 85 ff 13 00 4c ff a1 01 80 80 80 80 80 80 80 80 80 80 80 80 80 80 80 80 80 80 80 80 80 80 80 80 00 00 00 00 00 00 00 00 00 00 00 00 00 00 00 00 00 00 00 00 00 00 00 00 00 00 00 00 00 00 00 00 00 00 00 00 00 00 00 00 00 00 00 00 00 00 00 00 00 00 00 00 00 00 00 00 00 00 00 00 00 00 00 00 00 00 00 00 00 00 00 00 00 00 00 00 00 00 00 00 00 00 00 00 00 00 00 00 00 00 00 00 00 00 00 00 00 00 64 19 00 00 7e 01 d1 ff b2 ff 9f ff dc 01 85 ff 13 00 4c ff a1 01 80 80 80 80 80 80 80 80 80 80 80 80 80 80 80 80 80 80 80 80 80 80 80 80 00 00 00 00 00 00 00 00 00 00 00 00 00 00 00 00 00 00 00 00 00 00 00 00 00 00 00 00 00 00 00 00 00 00 00 00 00 00 00 00 00 00 00 00 00 00 00 00 00 00 00 00 00 00 00 00 00 00 00 00 00 00 00 00 00 00 00 00 00 00 00 00 00 00 00 00 00 00 00 00 00 00 00 00 00 00 00 00 00 00 00 00 00 00 00 00 00 00 74 0e 00 00 66 01 c5 ff d5 ff 74 ff b7 01 d5 ff 11 00 4c ff a2 01 80 80 80 80 80 80 80 80 80 80 80 80 80 80 80 80 80 80 80 80 80 80 80 80 00 00 00 00 00 00 00 00 00 00 00 00 00 00 00 00 00 00 00 00 00 00 00 00 00 00 00 00 00 00 00 00 00 00 00 00 00 00 00 00 00 00 00 00 00 00 00 00 00 00 00 00 00 00 00 00 00 00 00 00 00 00 00 00 00 00 00 00 00 00 00 00 00 00 00 00 00 00 00 00 00 00 00 00 00 00 00 00 00 00 00 00 00 00 00 00 00 00 f0 0a 00 00 d1 00 6d 00 c1 ff 68 ff b9 01 df ff f5 ff 3b ff d0 01 80 80 80 80 80 80 80 80 80 80 80 80 80 80 80 80 80 80 80 80 80 80 80 80 00 00 00 00 00 00 00 00 00 00 00 00 00 00 00 00 00 00 00 00 00 00 00 00 00 00 00 00 00 00 00 00 00 00 00 00 00 00 00 00 00 00 00 00 00 00 00 00 00 00 00 00 00 00 00 00 00 00 00 00 00 00 00 00 00 00 00 00 00 00 00 00 00 00 00 00 00 00 00 00 00 00 00 00 00 00 00 00 00 00 00 00 00 00 00 00 00 00];
		};
		iq_color {
			size = [ec 06 00 00];
			data = [00 00 00 00 80 80 40 10 00 00 00 00 00 00 00 00 00 00 00 00 00 14 0f 0a 05 00 00 00 00 00 00 00 00 00 05 0a 0f 00 00 00 6e 00 00 00 6e 00 00 00 78 00 00 00 80 00 00 00 80 00 00 00 80 00 00 00 80 00 00 00 80 00 00 00 80 00 00 00 80 00 00 00 80 00 00 00 80 00 00 00 80 00 00 00 80 00 00 00 80 00 00 00 80 00 00 00 80 00 00 00 80 80 40 10 00 00 00 00 00 00 00 00 00 00 00 00 00 14 0f 0a 05 00 00 00 00 00 00 00 00 00 05 0a 0f 00 00 00 6e 00 00 00 6e 00 00 00 78 00 00 00 80 00 00 00 80 00 00 00 80 00 00 00 80 00 00 00 80 00 00 00 80 00 00 00 80 00 00 00 80 00 00 00 80 00 00 00 80 00 00 00 80 00 00 00 80 00 00 00 80 00 00 00 80 00 00 00 80 80 40 10 00 00 00 00 00 00 00 00 00 00 00 00 00 14 0f 0a 05 00 00 00 00 00 00 00 00 00 05 0a 0f 00 00 00 6e 00 00 00 6e 00 00 00 78 00 00 00 80 00 00 00 80 00 00 00 80 00 00 00 80 00 00 00 80 00 00 00 80 00 00 00 80 00 00 00 80 00 00 00 80 00 00 00 80 00 00 00 80 00 00 00 80 00 00 00 80 00 00 00 80 00 00 00 80 80 40 10 00 00 00 00 00 00 00 00 00 00 00 00 00 14 0f 0a 05 00 00 00 00 00 00 00 00 00 05 0a 0f 00 00 00 6e 00 00 00 6e 00 00 00 78 00 00 00 80 00 00 00 80 00 00 00 80 00 00 00 80 00 00 00 80 00 00 00 80 00 00 00 80 00 00 00 80 00 00 00 80 00 00 00 80 00 00 00 80 00 00 00 80 00 00 00 80 00 00 00 80 00 00 00 80 80 40 10 00 00 00 00 00 00 00 00 00 00 00 00 00 14 0f 0a 05 00 00 00 00 00 00 00 00 00 05 0a 0f 00 00 00 6e 00 00 00 6e 00 00 00 78 00 00 00 80 00 00 00 80 00 00 00 80 00 00 00 80 00 00 00 80 00 00 00 80 00 00 00 80 00 00 00 80 00 00 00 80 00 00 00 80 00 00 00 80 00 00 00 80 00 00 00 80 00 00 00 80 00 00 00 80 80 40 10 00 00 00 00 00 00 00 00 00 00 00 00 00 14 0f 0a 05 00 00 00 00 00 00 00 00 00 05 0a 0f 00 00 00 6e 00 00 00 6e 00 00 00 78 00 00 00 80 00 00 00 80 00 00 00 80 00 00 00 80 00 00 00 80 00 00 00 80 00 00 00 80 00 00 00 80 00 00 00 80 00 00 00 80 00 00 00 80 00 00 00 80 00 00 00 80 00 00 00 80 00 00 00 80 c0 60 20 04 00 00 00 00 00 00 00 00 00 00 00 00 14 0f 0a 05 00 00 00 00 00 00 00 00 00 05 0a 0f 00 00 00 6e 00 00 00 6e 00 00 00 78 00 00 00 80 00 00 00 80 00 00 00 80 00 00 00 80 00 00 00 80 00 00 00 80 00 00 00 80 00 00 00 80 00 00 00 80 00 00 00 80 00 00 00 80 00 00 00 80 00 00 00 80 00 00 00 80 00 00 00 80 ff 80 40 10 00 00 00 00 00 00 00 00 00 00 00 00 14 0f 0a 05 00 00 00 00 00 00 00 00 00 05 0a 0f 00 00 00 6e 00 00 00 6e 00 00 00 78 00 00 00 80 00 00 00 80 00 00 00 80 00 00 00 80 00 00 00 80 00 00 00 80 00 00 00 80 00 00 00 80 00 00 00 80 00 00 00 80 00 00 00 80 00 00 00 80 00 00 00 80 00 00 00 80 00 00 00 80 ff c0 80 40 10 00 00 00 00 00 00 00 00 00 00 00 14 0f 0a 05 00 00 00 00 00 00 00 00 00 05 0a 0f 00 00 00 50 00 00 00 5a 00 00 00 6e 00 00 00 78 00 00 00 80 00 00 00 80 00 00 00 80 00 00 00 80 00 00 00 80 00 00 00 80 00 00 00 80 00 00 00 80 00 00 00 80 00 00 00 80 00 00 00 80 00 00 00 80 00 00 00 80 00 00 00 80 ff ff c0 80 40 10 00 00 00 00 00 00 00 00 00 00 14 0f 0a 05 00 00 00 00 00 00 00 00 00 05 0a 0f 00 00 00 50 00 00 00 5a 00 00 00 6e 00 00 00 78 00 00 00 80 00 00 00 80 00 00 00 80 00 00 00 80 00 00 00 80 00 00 00 80 00 00 00 80 00 00 00 80 00 00 00 80 00 00 00 80 00 00 00 80 00 00 00 80 00 00 00 80 00 00 00 80 ff ff c0 80 40 10 00 00 00 00 00 00 00 00 00 00 14 0f 0a 05 00 00 00 00 00 00 00 00 00 05 0a 0f 00 00 00 3c 00 00 00 50 00 00 00 5a 00 00 00 64 00 00 00 78 00 00 00 80 00 00 00 80 00 00 00 80 00 00 00 80 00 00 00 80 00 00 00 80 00 00 00 80 00 00 00 80 00 00 00 80 00 00 00 80 00 00 00 80 00 00 00 80 00 00 00 80 ff ff c0 80 40 10 00 00 00 00 00 00 00 00 00 00 14 0f 0a 05 00 00 00 00 00 00 00 00 00 05 0a 0f 00 00 00 3c 00 00 00 50 00 00 00 5a 00 00 00 64 00 00 00 78 00 00 00 80 00 00 00 80 00 00 00 80 00 00 00 80 00 00 00 80 00 00 00 80 00 00 00 80 00 00 00 80 00 00 00 80 00 00 00 80 00 00 00 80 00 00 00 80 00 00 00 80 ff ff c0 80 40 10 00 00 00 00 00 00 00 00 00 00 14 0f 0a 05 00 00 00 00 00 00 00 00 00 05 0a 0f 00 00 00 3c 00 00 00 50 00 00 00 5a 00 00 00 64 00 00 00 78 00 00 00 80 00 00 00 80 00 00 00 80 00 00 00 80 00 00 00 80 00 00 00 80 00 00 00 80 00 00 00 80 00 00 00 80 00 00 00 80 00 00 00 80 00 00 00 80 00 00 00 80 ff ff c0 80 40 10 00 00 00 00 00 00 00 00 00 00 14 0f 0a 05 00 00 00 00 00 00 00 00 00 05 0a 0f 00 00 00 3c 00 00 00 50 00 00 00 5a 00 00 00 64 00 00 00 78 00 00 00 80 00 00 00 80 00 00 00 80 00 00 00 80 00 00 00 80 00 00 00 80 00 00 00 80 00 00 00 80 00 00 00 80 00 00 00 80 00 00 00 80 00 00 00 80 00 00 00 80 ff ff c0 80 40 10 00 00 00 00 00 00 00 00 00 00 14 0f 0a 05 00 00 00 00 00 00 00 00 00 05 0a 0f 00 00 00 3c 00 00 00 50 00 00 00 5a 00 00 00 64 00 00 00 78 00 00 00 80 00 00 00 80 00 00 00 80 00 00 00 80 00 00 00 80 00 00 00 80 00 00 00 80 00 00 00 80 00 00 00 80 00 00 00 80 00 00 00 80 00 00 00 80 00 00 00 80 ff ff c0 80 40 10 00 00 00 00 00 00 00 00 00 00 14 0f 0a 05 00 00 00 00 00 00 00 00 00 05 0a 0f 00 00 00 3c 00 00 00 50 00 00 00 5a 00 00 00 64 00 00 00 78 00 00 00 80 00 00 00 80 00 00 00 80 00 00 00 80 00 00 00 80 00 00 00 80 00 00 00 80 00 00 00 80 00 00 00 80 00 00 00 80 00 00 00 80 00 00 00 80 00 00 00 80 ff ff c0 80 40 10 00 00 00 00 00 00 00 00 00 00 14 0f 0a 05 00 00 00 00 00 00 00 00 00 05 0a 0f 00 00 00 3c 00 00 00 50 00 00 00 5a 00 00 00 64 00 00 00 78 00 00 00 80 00 00 00 80 00 00 00 80 00 00 00 80 00 00 00 80 00 00 00 80 00 00 00 80 00 00 00 80 00 00 00 80 00 00 00 80 00 00 00 80 00 00 00 80 00 00 00];
		};
		iq_contrast {
			size = [b0 00 00 00];
			data = [00 00 00 00 80 00 00 00 00 00 00 00 00 00 80 0a 0a 0a 0a 0a 0a 0a 0a 0a 80 0a 0a 0a 0a 0a 0a 0a 0a 0a 80 0a 0a 0a 0a 0a 0a 0a 0a 0a 80 0a 0a 0a 0a 0a 0a 0a 0a 0a 80 05 05 05 05 05 05 05 05 05 80 05 05 05 05 05 05 05 05 05 80 00 00 00 00 00 00 00 00 00 80 00 00 00 00 00 00 00 00 00 80 00 00 00 00 00 00 00 00 00 80 00 00 00 00 00 00 00 00 00 80 00 00 00 00 00 00 00 00 00 80 00 00 00 00 00 00 00 00 00 80 00 00 00 00 00 00 00 00 00 80 00 00 00 00 00 00 00 00 00 80 00 00 00 00 00 00 00 00 00 80 00 00 00 00 00 00 00 00 00 00 00];
		};
		iq_edge {
			size = [e0 05 00 00];
			data = [01 00 00 00 00 00 00 00 80 00 00 00 31 00 00 00 64 78 8c a0 b4 c8 e0 ff ff e0 c0 aa 9a 90 88 80 20 2d 35 40 40 40 40 40 40 40 40 40 40 35 2d 20 80 80 80 80 80 80 80 80 80 80 80 80 80 80 80 80 80 80 80 80 80 80 80 80 40 00 00 00 80 00 00 00 80 00 00 00 08 00 00 00 00 00 00 00 00 00 00 00 10 00 00 00 08 00 00 00 28 00 00 00 f0 00 00 00 00 01 00 00 40 50 00 00 00 01 00 00 00 01 00 00 00 00 00 00 80 00 00 00 00 00 00 00 02 00 00 00 00 00 00 00 00 02 00 00 00 00 00 00 05 00 00 00 64 00 00 00 64 00 00 00 10 00 00 00 00 00 00 00 10 00 00 00 10 00 00 00 12 00 00 00 32 00 00 00 64 00 00 00 84 00 00 00 30 50 00 00 00 01 00 00 00 01 00 00 00 00 00 00 50 00 00 00 00 00 00 00 05 00 00 00 00 00 00 00 00 02 00 00 00 00 00 00 05 00 00 00 64 00 00 00 64 00 00 00 10 00 00 00 00 00 00 00 10 00 00 00 10 00 00 00 1c 00 00 00 3c 00 00 00 6e 00 00 00 8e 00 00 00 30 50 00 00 00 01 00 00 00 01 00 00 00 00 00 00 50 00 00 00 00 00 00 00 05 00 00 00 00 00 00 00 00 02 00 00 00 00 00 00 05 00 00 00 64 00 00 00 64 00 00 00 10 00 00 00 00 00 00 00 10 00 00 00 10 00 00 00 20 00 00 00 50 00 00 00 78 00 00 00 98 00 00 00 30 50 00 00 00 01 00 00 00 01 00 00 00 00 00 00 50 00 00 00 00 00 00 00 05 00 00 00 00 00 00 00 00 02 00 00 00 00 00 00 05 00 00 00 64 00 00 00 64 00 00 00 10 00 00 00 00 00 00 00 10 00 00 00 10 00 00 00 24 00 00 00 64 00 00 00 82 00 00 00 a2 00 00 00 28 50 00 00 00 01 00 00 00 01 00 00 00 00 00 00 50 00 00 00 00 00 00 00 05 00 00 00 00 00 00 00 00 02 00 00 00 00 00 00 05 00 00 00 64 00 00 00 64 00 00 00 10 00 00 00 00 00 00 00 0c 00 00 00 0c 00 00 00 2e 00 00 00 6e 00 00 00 8c 00 00 00 ac 00 00 00 20 50 00 00 00 01 00 00 00 01 00 00 00 00 00 00 50 00 00 00 00 00 00 00 05 00 00 00 00 00 00 00 00 02 00 00 00 00 00 00 05 00 00 00 64 00 00 00 64 00 00 00 10 00 00 00 00 00 00 00 08 00 00 00 08 00 00 00 56 00 00 00 96 00 00 00 b4 00 00 00 d4 00 00 00 20 50 00 00 00 01 00 00 00 01 00 00 00 00 00 00 50 00 00 00 00 00 00 00 05 00 00 00 00 00 00 00 00 02 00 00 00 00 00 00 05 00 00 00 64 00 00 00 64 00 00 00 10 00 00 00 00 00 00 00 08 00 00 00 08 00 00 00 b0 00 00 00 f0 00 00 00 0e 01 00 00 2e 01 00 00 20 50 00 00 00 01 00 00 00 01 00 00 00 00 00 00 50 00 00 00 00 00 00 00 05 00 00 00 00 00 00 00 00 02 00 00 00 00 00 00 05 00 00 00 64 00 00 00 64 00 00 00 10 00 00 00 00 00 00 00 08 00 00 00 08 00 00 00 0a 01 00 00 4a 01 00 00 68 01 00 00 88 01 00 00 20 50 00 00 00 01 00 00 00 01 00 00 00 00 00 00 50 00 00 00 00 00 00 00 05 00 00 00 00 00 00 00 00 02 00 00 00 00 00 00 05 00 00 00 64 00 00 00 64 00 00 00 10 00 00 00 00 00 00 00 04 00 00 00 04 00 00 00 32 01 00 00 72 01 00 00 90 01 00 00 b0 01 00 00 20 50 00 00 00 01 00 00 00 01 00 00 00 00 00 00 50 00 00 00 00 00 00 00 05 00 00 00 00 00 00 00 00 02 00 00 00 00 00 00 05 00 00 00 5a 00 00 00 5a 00 00 00 10 00 00 00 00 00 00 00 02 00 00 00 02 00 00 00 5e 01 00 00 c2 01 00 00 e0 01 00 00 00 02 00 00 20 50 00 00 00 01 00 00 00 01 00 00 00 00 00 00 50 00 00 00 02 00 00 00 05 00 00 00 00 00 00 00 00 02 00 00 00 00 00 00 05 00 00 00 50 00 00 00 50 00 00 00 10 00 00 00 00 00 00 00 00 00 00 00 00 00 00 00 c2 01 00 00 f4 01 00 00 12 02 00 00 32 02 00 00 10 50 00 00 00 01 00 00 00 01 00 00 00 00 00 00 50 00 00 00 02 00 00 00 05 00 00 00 00 00 00 00 00 02 00 00 00 00 00 00 05 00 00 00 50 00 00 00 50 00 00 00 10 00 00 00 00 00 00 00 00 00 00 00 00 00 00 00 c2 01 00 00 f4 01 00 00 12 02 00 00 32 02 00 00 10 50 00 00 00 01 00 00 00 01 00 00 00 00 00 00 50 00 00 00 02 00 00 00 05 00 00 00 00 00 00 00 00 02 00 00 00 00 00 00 05 00 00 00 50 00 00 00 50 00 00 00 10 00 00 00 00 00 00 00 00 00 00 00 00 00 00 00 c2 01 00 00 f4 01 00 00 12 02 00 00 32 02 00 00 10 50 00 00 00 01 00 00 00 01 00 00 00 00 00 00 50 00 00 00 02 00 00 00 05 00 00 00 00 00 00 00 00 02 00 00 00 00 00 00 05 00 00 00 50 00 00 00 50 00 00 00 10 00 00 00 00 00 00 00 00 00 00 00 00 00 00 00 c2 01 00 00 f4 01 00 00 12 02 00 00 32 02 00 00 10 50 00 00 00 01 00 00 00 01 00 00 00 00 00 00 50 00 00 00 02 00 00 00 05 00 00 00 00 00 00 00 00 02 00 00 00 00 00 00 05 00 00 00 50 00 00 00 50 00 00 00 10 00 00 00 00 00 00 00 00 00 00 00 00 00 00 00 c2 01 00 00 f4 01 00 00 12 02 00 00 32 02 00 00 10 50 00 00 00 01 00 00 00 01 00 00 00 00 00 00 50 00 00 00 02 00 00 00 05 00 00 00 00 00 00 00 00 02 00 00 00 00 00 00 05 00 00 00 50 00 00 00 50 00 00 00 10 00 00 00 00 00 00 00 00 00 00 00 00 00 00 00 c2 01 00 00 f4 01 00 00 12 02 00 00 32 02 00 00 10 50 00 00 00 01 00 00 00 01 00 00 00 00 00 00 50 00 00 00 02 00 00 00 05 00 00 00 00 00 00 00 00 02 00 00 00 00 00 00 05 00 00 00];
		};
		iq_3dnr {
			size = [64 1f 00 00];
			data = [01 00 00 00 00 00 00 00 00 00 00 00 00 00 00 00 0f 00 00 00 40 00 00 00 40 00 00 00 00 00 00 00 80 00 00 00 80 00 00 00 80 00 00 00 c8 00 00 00 c8 00 00 00 04 00 00 00 04 00 00 00 03 00 00 00 04 00 00 00 04 00 00 00 04 00 00 00 04 00 00 00 04 00 00 00 05 00 00 00 05 00 00 00 06 00 00 00 06 00 00 00 07 00 00 00 07 00 00 00 08 00 00 00 08 00 00 00 80 00 00 00 04 00 00 00 00 00 00 00 00 00 00 00 00 00 00 00 00 00 00 00 00 00 00 00 00 00 00 00 00 00 00 00 00 00 00 00 00 00 00 00 00 00 00 00 00 00 00 00 00 00 00 00 00 00 00 00 00 00 00 00 00 00 00 00 00 00 00 00 00 00 00 00 00 00 00 00 00 00 00 00 00 00 00 00 00 00 00 00 00 00 00 00 00 00 00 00 00 00 00 00 00 00 00 00 00 00 00 00 00 00 00 00 00 00 00 00 00 00 00 00 00 00 00 00 00 00 00 00 00 00 00 00 08 00 00 00 10 00 00 00 04 00 00 00 10 00 00 00 20 00 00 00 06 00 00 00 01 01 01 00 01 00 00 00 00 00 00 00 00 00 00 00 00 00 00 00 10 00 00 00 20 00 00 00 30 00 00 00 40 00 00 00 80 00 00 00 40 00 00 00 00 01 00 00 00 01 00 00 10 00 00 00 10 00 00 00 10 00 00 00 10 00 00 00 10 00 00 00 10 00 00 00 10 00 00 00 10 00 00 00 10 00 00 00 10 00 00 00 10 00 00 00 10 00 00 00 08 00 00 00 10 00 00 00 40 00 00 00 40 00 00 00 10 00 00 00 08 00 00 00 00 00 00 00 06 00 00 00 0c 00 00 00 18 00 00 00 28 00 00 00 4c 00 00 00 60 00 00 00 70 00 00 00 80 00 00 00 40 00 00 00 00 00 00 00 06 00 00 00 0c 00 00 00 18 00 00 00 28 00 00 00 4c 00 00 00 60 00 00 00 70 00 00 00 80 00 00 00 40 00 00 00 04 01 00 00 00 00 00 00 08 00 00 00 20 00 00 00 20 00 00 00 00 00 00 00 30 00 00 00 30 00 00 00 30 00 00 00 40 00 00 00 40 00 00 00 04 00 00 00 04 00 00 00 03 00 00 00 04 00 00 00 04 00 00 00 04 00 00 00 04 00 00 00 04 00 00 00 06 00 00 00 06 00 00 00 06 00 00 00 06 00 00 00 06 00 00 00 07 00 00 00 07 00 00 00 08 00 00 00 b4 00 00 00 08 00 00 00 c8 00 00 00 c8 00 00 00 c8 00 00 00 64 00 00 00 64 00 00 00 64 00 00 00 64 00 00 00 64 00 00 00 07 00 00 00 08 00 00 00 07 00 00 00 07 00 00 00 06 00 00 00 06 00 00 00 06 00 00 00 06 00 00 00 50 00 00 00 5a 00 00 00 50 00 00 00 46 00 00 00 3c 00 00 00 3c 00 00 00 3c 00 00 00 3c 00 00 00 19 00 00 00 1e 00 00 00 19 00 00 00 14 00 00 00 14 00 00 00 14 00 00 00 14 00 00 00 14 00 00 00 08 00 00 00 10 00 00 00 03 00 00 00 10 00 00 00 20 00 00 00 03 00 00 00 01 02 02 00 01 00 00 00 00 00 00 10 00 00 10 00 00 00 00 00 08 00 00 00 0a 00 00 00 0c 00 00 00 0e 00 00 00 40 00 00 00 10 00 00 00 2c 01 00 00 c8 00 00 00 20 00 00 00 20 00 00 00 20 00 00 00 20 00 00 00 10 00 00 00 10 00 00 00 10 00 00 00 10 00 00 00 10 00 00 00 10 00 00 00 10 00 00 00 10 00 00 00 00 00 00 00 10 00 00 00 20 00 00 00 10 00 00 00 04 00 00 00 02 00 00 00 00 00 00 00 0c 00 00 00 18 00 00 00 2b 00 00 00 3e 00 00 00 50 00 00 00 60 00 00 00 70 00 00 00 40 00 00 00 20 00 00 00 00 00 00 00 09 00 00 00 16 00 00 00 28 00 00 00 39 00 00 00 4b 00 00 00 60 00 00 00 70 00 00 00 80 00 00 00 40 00 00 00 04 01 00 00 00 00 00 00 08 00 00 00 20 00 00 00 20 00 00 00 00 00 00 00 40 00 00 00 40 00 00 00 40 00 00 00 50 00 00 00 50 00 00 00 04 00 00 00 04 00 00 00 03 00 00 00 04 00 00 00 04 00 00 00 04 00 00 00 04 00 00 00 04 00 00 00 06 00 00 00 06 00 00 00 06 00 00 00 06 00 00 00 06 00 00 00 07 00 00 00 07 00 00 00 08 00 00 00 b4 00 00 00 08 00 00 00 c8 00 00 00 c8 00 00 00 c8 00 00 00 64 00 00 00 64 00 00 00 64 00 00 00 64 00 00 00 64 00 00 00 08 00 00 00 09 00 00 00 08 00 00 00 08 00 00 00 07 00 00 00 07 00 00 00 07 00 00 00 07 00 00 00 50 00 00 00 5a 00 00 00 50 00 00 00 46 00 00 00 3c 00 00 00 3c 00 00 00 3c 00 00 00 3c 00 00 00 19 00 00 00 1e 00 00 00 19 00 00 00 14 00 00 00 14 00 00 00 14 00 00 00 14 00 00 00 14 00 00 00 08 00 00 00 10 00 00 00 03 00 00 00 10 00 00 00 20 00 00 00 03 00 00 00 01 02 02 00 01 00 00 00 00 00 00 10 00 00 10 00 00 00 00 00 08 00 00 00 0a 00 00 00 0c 00 00 00 0e 00 00 00 40 00 00 00 10 00 00 00 90 01 00 00 2c 01 00 00 20 00 00 00 20 00 00 00 20 00 00 00 20 00 00 00 10 00 00 00 10 00 00 00 10 00 00 00 10 00 00 00 10 00 00 00 10 00 00 00 10 00 00 00 10 00 00 00 00 00 00 00 10 00 00 00 20 00 00 00 10 00 00 00 04 00 00 00 02 00 00 00 00 00 00 00 0a 00 00 00 16 00 00 00 28 00 00 00 3e 00 00 00 50 00 00 00 60 00 00 00 70 00 00 00 40 00 00 00 20 00 00 00 00 00 00 00 09 00 00 00 16 00 00 00 28 00 00 00 39 00 00 00 4b 00 00 00 60 00 00 00 70 00 00 00 80 00 00 00 40 00 00 00 04 01 00 00 00 00 00 00 08 00 00 00 40 00 00 00 40 00 00 00 00 00 00 00 60 00 00 00 60 00 00 00 60 00 00 00 9c 00 00 00 9c 00 00 00 04 00 00 00 04 00 00 00 03 00 00 00 04 00 00 00 04 00 00 00 04 00 00 00 04 00 00 00 04 00 00 00 06 00 00 00 06 00 00 00 06 00 00 00 06 00 00 00 06 00 00 00 07 00 00 00 07 00 00 00 08 00 00 00 b4 00 00 00 08 00 00 00 c8 00 00 00 c8 00 00 00 c8 00 00 00 64 00 00 00 64 00 00 00 64 00 00 00 64 00 00 00 64 00 00 00 09 00 00 00 0a 00 00 00 09 00 00 00 09 00 00 00 08 00 00 00 08 00 00 00 08 00 00 00 08 00 00 00 5a 00 00 00 64 00 00 00 5a 00 00 00 46 00 00 00 3c 00 00 00 3c 00 00 00 3c 00 00 00 3c 00 00 00 1e 00 00 00 28 00 00 00 1e 00 00 00 19 00 00 00 19 00 00 00 19 00 00 00 19 00 00 00 19 00 00 00 08 00 00 00 10 00 00 00 03 00 00 00 10 00 00 00 20 00 00 00 03 00 00 00 01 02 02 00 01 00 00 00 00 80 80 10 00 00 10 00 00 00 00 00 0c 00 00 00 0f 00 00 00 12 00 00 00 16 00 00 00 40 00 00 00 20 00 00 00 90 01 00 00 90 01 00 00 20 00 00 00 20 00 00 00 20 00 00 00 20 00 00 00 10 00 00 00 10 00 00 00 10 00 00 00 10 00 00 00 10 00 00 00 10 00 00 00 10 00 00 00 10 00 00 00 00 00 00 00 10 00 00 00 20 00 00 00 20 00 00 00 04 00 00 00 02 00 00 00 00 00 00 00 0a 00 00 00 16 00 00 00 28 00 00 00 3e 00 00 00 50 00 00 00 60 00 00 00 70 00 00 00 40 00 00 00 20 00 00 00 00 00 00 00 09 00 00 00 16 00 00 00 28 00 00 00 39 00 00 00 4b 00 00 00 60 00 00 00 70 00 00 00 80 00 00 00 40 00 00 00 04 01 00 00 01 00 00 00 08 00 00 00 50 00 00 00 50 00 00 00 00 00 00 00 80 00 00 00 80 00 00 00 80 00 00 00 00 01 00 00 00 01 00 00 04 00 00 00 04 00 00 00 03 00 00 00 04 00 00 00 04 00 00 00 04 00 00 00 04 00 00 00 04 00 00 00 06 00 00 00 06 00 00 00 06 00 00 00 06 00 00 00 06 00 00 00 07 00 00 00 07 00 00 00 08 00 00 00 8c 00 00 00 06 00 00 00 c8 00 00 00 c8 00 00 00 c8 00 00 00 64 00 00 00 64 00 00 00 64 00 00 00 64 00 00 00 64 00 00 00 0a 00 00 00 0b 00 00 00 0a 00 00 00 0a 00 00 00 09 00 00 00 09 00 00 00 09 00 00 00 09 00 00 00 64 00 00 00 6e 00 00 00 64 00 00 00 50 00 00 00 46 00 00 00 46 00 00 00 46 00 00 00 46 00 00 00 23 00 00 00 2d 00 00 00 23 00 00 00 1e 00 00 00 1e 00 00 00 1e 00 00 00 1e 00 00 00 1e 00 00 00 08 00 00 00 10 00 00 00 03 00 00 00 10 00 00 00 20 00 00 00 03 00 00 00 01 03 03 00 01 00 00 00 00 80 80 10 00 00 10 00 00 00 00 00 0c 00 00 00 0f 00 00 00 12 00 00 00 16 00 00 00 40 00 00 00 20 00 00 00 90 01 00 00 90 01 00 00 20 00 00 00 20 00 00 00 20 00 00 00 20 00 00 00 10 00 00 00 10 00 00 00 10 00 00 00 10 00 00 00 10 00 00 00 10 00 00 00 10 00 00 00 10 00 00 00 00 00 00 00 10 00 00 00 20 00 00 00 20 00 00 00 08 00 00 00 02 00 00 00 00 00 00 00 0a 00 00 00 16 00 00 00 28 00 00 00 3e 00 00 00 50 00 00 00 60 00 00 00 70 00 00 00 40 00 00 00 20 00 00 00 00 00 00 00 09 00 00 00 16 00 00 00 28 00 00 00 39 00 00 00 4b 00 00 00 60 00 00 00 70 00 00 00 80 00 00 00 40 00 00 00 04 01 00 00 01 00 00 00 08 00 00 00 60 00 00 00 60 00 00 00 00 00 00 00 c0 00 00 00 c0 00 00 00 c0 00 00 00 80 01 00 00 80 01 00 00 04 00 00 00 04 00 00 00 03 00 00 00 04 00 00 00 04 00 00 00 04 00 00 00 04 00 00 00 04 00 00 00 06 00 00 00 06 00 00 00 06 00 00 00 06 00 00 00 06 00 00 00 07 00 00 00 07 00 00 00 08 00 00 00 80 00 00 00 06 00 00 00 c8 00 00 00 c8 00 00 00 c8 00 00 00 64 00 00 00 64 00 00 00 64 00 00 00 64 00 00 00 64 00 00 00 0b 00 00 00 0c 00 00 00 0b 00 00 00 0b 00 00 00 0a 00 00 00 0a 00 00 00 0a 00 00 00 0a 00 00 00 6e 00 00 00 78 00 00 00 6e 00 00 00 5a 00 00 00 50 00 00 00 50 00 00 00 50 00 00 00 50 00 00 00 28 00 00 00 32 00 00 00 28 00 00 00 23 00 00 00 23 00 00 00 23 00 00 00 23 00 00 00 23 00 00 00 08 00 00 00 10 00 00 00 03 00 00 00 10 00 00 00 20 00 00 00 03 00 00 00 01 03 03 00 01 00 00 00 00 ff ff 40 04 02 40 04 02 00 00 00 10 00 00 00 14 00 00 00 18 00 00 00 1c 00 00 00 40 00 00 00 20 00 00 00 90 01 00 00 90 01 00 00 20 00 00 00 20 00 00 00 20 00 00 00 20 00 00 00 10 00 00 00 10 00 00 00 10 00 00 00 10 00 00 00 10 00 00 00 10 00 00 00 10 00 00 00 10 00 00 00 00 00 00 00 10 00 00 00 20 00 00 00 20 00 00 00 08 00 00 00 02 00 00 00 00 00 00 00 0a 00 00 00 16 00 00 00 28 00 00 00 3e 00 00 00 50 00 00 00 60 00 00 00 70 00 00 00 40 00 00 00 20 00 00 00 00 00 00 00 09 00 00 00 16 00 00 00 28 00 00 00 39 00 00 00 4b 00 00 00 60 00 00 00 70 00 00 00 80 00 00 00 40 00 00 00 04 01 00 00 01 00 00 00 08 00 00 00 60 00 00 00 60 00 00 00 00 00 00 00 c0 00 00 00 c0 00 00 00 c0 00 00 00 80 01 00 00 80 01 00 00 04 00 00 00 04 00 00 00 03 00 00 00 04 00 00 00 04 00 00 00 04 00 00 00 04 00 00 00 04 00 00 00 06 00 00 00 06 00 00 00 06 00 00 00 06 00 00 00 06 00 00 00 07 00 00 00 07 00 00 00 08 00 00 00 80 00 00 00 06 00 00 00 c8 00 00 00 c8 00 00 00 c8 00 00 00 64 00 00 00 64 00 00 00 64 00 00 00 64 00 00 00 64 00 00 00 0c 00 00 00 0d 00 00 00 0c 00 00 00 0c 00 00 00 0b 00 00 00 0b 00 00 00 0b 00 00 00 13 00 00 00 78 00 00 00 82 00 00 00 78 00 00 00 64 00 00 00 5a 00 00 00 5a 00 00 00 5a 00 00 00 5a 00 00 00 2d 00 00 00 37 00 00 00 2d 00 00 00 28 00 00 00 28 00 00 00 28 00 00 00 28 00 00 00 28 00 00 00 08 00 00 00 10 00 00 00 03 00 00 00 10 00 00 00 20 00 00 00 03 00 00 00 01 02 01 00 01 00 00 00 00 ff ff 40 04 02 40 04 02 00 00 00 10 00 00 00 14 00 00 00 18 00 00 00 1c 00 00 00 40 00 00 00 20 00 00 00 f4 01 00 00 f4 01 00 00 20 00 00 00 20 00 00 00 20 00 00 00 20 00 00 00 10 00 00 00 10 00 00 00 10 00 00 00 10 00 00 00 10 00 00 00 10 00 00 00 10 00 00 00 10 00 00 00 00 00 00 00 10 00 00 00 20 00 00 00 20 00 00 00 08 00 00 00 02 00 00 00 00 00 00 00 0a 00 00 00 16 00 00 00 28 00 00 00 3e 00 00 00 50 00 00 00 60 00 00 00 70 00 00 00 40 00 00 00 20 00 00 00 00 00 00 00 09 00 00 00 16 00 00 00 28 00 00 00 39 00 00 00 4b 00 00 00 60 00 00 00 70 00 00 00 80 00 00 00 40 00 00 00 04 01 00 00 01 00 00 00 08 00 00 00 80 00 00 00 80 00 00 00 00 00 00 00 e1 00 00 00 e1 00 00 00 e1 00 00 00 e0 01 00 00 e0 01 00 00 04 00 00 00 04 00 00 00 03 00 00 00 04 00 00 00 04 00 00 00 04 00 00 00 04 00 00 00 04 00 00 00 06 00 00 00 06 00 00 00 06 00 00 00 06 00 00 00 06 00 00 00 07 00 00 00 07 00 00 00 08 00 00 00 80 00 00 00 06 00 00 00 c8 00 00 00 c8 00 00 00 c8 00 00 00 64 00 00 00 64 00 00 00 64 00 00 00 64 00 00 00 64 00 00 00 0d 00 00 00 0e 00 00 00 0d 00 00 00 0d 00 00 00 0c 00 00 00 0c 00 00 00 0c 00 00 00 14 00 00 00 a0 00 00 00 aa 00 00 00 a0 00 00 00 8c 00 00 00 82 00 00 00 82 00 00 00 82 00 00 00 82 00 00 00 32 00 00 00 3c 00 00 00 32 00 00 00 2d 00 00 00 2d 00 00 00 2d 00 00 00 2d 00 00 00 2d 00 00 00 08 00 00 00 10 00 00 00 03 00 00 00 10 00 00 00 20 00 00 00 03 00 00 00 01 02 02 00 01 00 00 00 00 ff ff 40 04 02 40 04 02 00 00 00 14 00 00 00 1e 00 00 00 28 00 00 00 32 00 00 00 80 00 00 00 40 00 00 00 f4 01 00 00 f4 01 00 00 20 00 00 00 20 00 00 00 20 00 00 00 20 00 00 00 10 00 00 00 10 00 00 00 10 00 00 00 10 00 00 00 10 00 00 00 10 00 00 00 10 00 00 00 10 00 00 00 00 00 00 00 10 00 00 00 20 00 00 00 20 00 00 00 08 00 00 00 02 00 00 00 00 00 00 00 0a 00 00 00 16 00 00 00 28 00 00 00 3e 00 00 00 50 00 00 00 60 00 00 00 70 00 00 00 80 00 00 00 40 00 00 00 00 00 00 00 09 00 00 00 16 00 00 00 28 00 00 00 39 00 00 00 4b 00 00 00 60 00 00 00 70 00 00 00 80 00 00 00 40 00 00 00 04 01 00 00 02 00 00 00 08 00 00 00 5e 01 00 00 5e 01 00 00 00 00 00 00 bc 02 00 00 bc 02 00 00 bc 02 00 00 84 03 00 00 84 03 00 00 04 00 00 00 04 00 00 00 03 00 00 00 04 00 00 00 04 00 00 00 04 00 00 00 04 00 00 00 04 00 00 00 06 00 00 00 06 00 00 00 06 00 00 00 06 00 00 00 06 00 00 00 07 00 00 00 07 00 00 00 08 00 00 00 80 00 00 00 05 00 00 00 c8 00 00 00 c8 00 00 00 c8 00 00 00 64 00 00 00 64 00 00 00 64 00 00 00 64 00 00 00 64 00 00 00 0e 00 00 00 0f 00 00 00 0e 00 00 00 0e 00 00 00 0d 00 00 00 0d 00 00 00 0d 00 00 00 0d 00 00 00 54 01 00 00 54 01 00 00 18 01 00 00 d2 00 00 00 c8 00 00 00 c8 00 00 00 c8 00 00 00 c8 00 00 00 4b 00 00 00 4b 00 00 00 41 00 00 00 3c 00 00 00 32 00 00 00 32 00 00 00 32 00 00 00 32 00 00 00 08 00 00 00 10 00 00 00 03 00 00 00 10 00 00 00 20 00 00 00 03 00 00 00 01 02 03 00 01 00 00 00 20 ff ff 40 04 02 40 04 02 00 00 00 1e 00 00 00 28 00 00 00 32 00 00 00 3c 00 00 00 80 00 00 00 40 00 00 00 bc 02 00 00 bc 02 00 00 20 00 00 00 20 00 00 00 20 00 00 00 20 00 00 00 10 00 00 00 10 00 00 00 10 00 00 00 10 00 00 00 10 00 00 00 10 00 00 00 10 00 00 00 10 00 00 00 00 00 00 00 10 00 00 00 40 00 00 00 20 00 00 00 08 00 00 00 02 00 00 00 00 00 00 00 0a 00 00 00 16 00 00 00 28 00 00 00 3e 00 00 00 50 00 00 00 60 00 00 00 70 00 00 00 80 00 00 00 40 00 00 00 00 00 00 00 08 00 00 00 14 00 00 00 24 00 00 00 37 00 00 00 4b 00 00 00 60 00 00 00 70 00 00 00 00 00 00 00 00 00 00 00 04 01 00 00 02 00 00 00 08 00 00 00 90 01 00 00 90 01 00 00 00 00 00 00 20 03 00 00 20 03 00 00 20 03 00 00 ff 03 00 00 ff 03 00 00 03 00 00 00 03 00 00 00 02 00 00 00 03 00 00 00 03 00 00 00 03 00 00 00 03 00 00 00 03 00 00 00 06 00 00 00 06 00 00 00 06 00 00 00 06 00 00 00 06 00 00 00 07 00 00 00 07 00 00 00 08 00 00 00 80 00 00 00 05 00 00 00 c8 00 00 00 c8 00 00 00 c8 00 00 00 64 00 00 00 64 00 00 00 64 00 00 00 64 00 00 00 64 00 00 00 0f 00 00 00 10 00 00 00 0f 00 00 00 0f 00 00 00 0e 00 00 00 0e 00 00 00 0e 00 00 00 12 00 00 00 b8 01 00 00 b8 01 00 00 7c 01 00 00 36 01 00 00 2c 01 00 00 2c 01 00 00 2c 01 00 00 2c 01 00 00 4b 00 00 00 4b 00 00 00 41 00 00 00 3c 00 00 00 32 00 00 00 32 00 00 00 32 00 00 00 32 00 00 00 08 00 00 00 10 00 00 00 03 00 00 00 10 00 00 00 20 00 00 00 03 00 00 00 01 02 03 00 01 00 00 00 20 ff ff 40 04 02 40 04 02 00 00 00 28 00 00 00 37 00 00 00 46 00 00 00 55 00 00 00 80 00 00 00 40 00 00 00 bc 02 00 00 bc 02 00 00 20 00 00 00 20 00 00 00 20 00 00 00 20 00 00 00 10 00 00 00 10 00 00 00 10 00 00 00 10 00 00 00 10 00 00 00 10 00 00 00 10 00 00 00 10 00 00 00 00 00 00 00 10 00 00 00 40 00 00 00 20 00 00 00 08 00 00 00 02 00 00 00 00 00 00 00 0a 00 00 00 16 00 00 00 28 00 00 00 3e 00 00 00 50 00 00 00 60 00 00 00 70 00 00 00 80 00 00 00 40 00 00 00 00 00 00 00 06 00 00 00 12 00 00 00 22 00 00 00 37 00 00 00 4b 00 00 00 60 00 00 00 70 00 00 00 00 00 00 00 00 00 00 00 04 01 00 00 02 00 00 00 08 00 00 00 90 01 00 00 90 01 00 00 00 00 00 00 20 03 00 00 20 03 00 00 20 03 00 00 ff 03 00 00 ff 03 00 00 02 00 00 00 02 00 00 00 01 00 00 00 02 00 00 00 02 00 00 00 02 00 00 00 02 00 00 00 02 00 00 00 06 00 00 00 06 00 00 00 06 00 00 00 06 00 00 00 06 00 00 00 07 00 00 00 07 00 00 00 08 00 00 00 80 00 00 00 05 00 00 00 c8 00 00 00 c8 00 00 00 c8 00 00 00 64 00 00 00 64 00 00 00 64 00 00 00 64 00 00 00 64 00 00 00 10 00 00 00 11 00 00 00 10 00 00 00 10 00 00 00 0f 00 00 00 0f 00 00 00 0f 00 00 00 0f 00 00 00 1c 02 00 00 1c 02 00 00 e0 01 00 00 9a 01 00 00 90 01 00 00 90 01 00 00 90 01 00 00 90 01 00 00 55 00 00 00 55 00 00 00 4b 00 00 00 46 00 00 00 3c 00 00 00 3c 00 00 00 3c 00 00 00 3c 00 00 00 08 00 00 00 10 00 00 00 03 00 00 00 10 00 00 00 20 00 00 00 03 00 00 00 01 02 03 00 01 00 00 00 20 ff ff 40 04 02 40 04 02 00 00 00 37 00 00 00 46 00 00 00 55 00 00 00 8c 00 00 00 80 00 00 00 40 00 00 00 e8 03 00 00 bc 02 00 00 20 00 00 00 20 00 00 00 20 00 00 00 20 00 00 00 10 00 00 00 10 00 00 00 10 00 00 00 10 00 00 00 10 00 00 00 10 00 00 00 10 00 00 00 10 00 00 00 00 00 00 00 10 00 00 00 40 00 00 00 20 00 00 00 08 00 00 00 02 00 00 00 00 00 00 00 08 00 00 00 14 00 00 00 26 00 00 00 3c 00 00 00 50 00 00 00 60 00 00 00 70 00 00 00 80 00 00 00 40 00 00 00 00 00 00 00 06 00 00 00 12 00 00 00 22 00 00 00 37 00 00 00 4b 00 00 00 60 00 00 00 70 00 00 00 00 00 00 00 00 00 00 00 04 01 00 00 02 00 00 00 08 00 00 00 90 01 00 00 90 01 00 00 00 00 00 00 20 03 00 00 20 03 00 00 20 03 00 00 ff 03 00 00 ff 03 00 00 02 00 00 00 02 00 00 00 01 00 00 00 02 00 00 00 02 00 00 00 02 00 00 00 02 00 00 00 02 00 00 00 06 00 00 00 06 00 00 00 06 00 00 00 06 00 00 00 06 00 00 00 07 00 00 00 07 00 00 00 08 00 00 00 80 00 00 00 05 00 00 00 c8 00 00 00 c8 00 00 00 c8 00 00 00 64 00 00 00 64 00 00 00 64 00 00 00 64 00 00 00 64 00 00 00 11 00 00 00 13 00 00 00 11 00 00 00 11 00 00 00 10 00 00 00 10 00 00 00 10 00 00 00 10 00 00 00 80 02 00 00 80 02 00 00 4e 02 00 00 1c 02 00 00 b8 01 00 00 b8 01 00 00 b8 01 00 00 b8 01 00 00 5f 00 00 00 5f 00 00 00 55 00 00 00 50 00 00 00 46 00 00 00 46 00 00 00 46 00 00 00 46 00 00 00 08 00 00 00 10 00 00 00 03 00 00 00 10 00 00 00 20 00 00 00 03 00 00 00 01 02 02 00 01 00 00 00 20 ff ff 40 04 02 40 04 02 00 00 00 46 00 00 00 55 00 00 00 64 00 00 00 73 00 00 00 80 00 00 00 40 00 00 00 e8 03 00 00 e8 03 00 00 20 00 00 00 20 00 00 00 20 00 00 00 20 00 00 00 10 00 00 00 10 00 00 00 10 00 00 00 10 00 00 00 10 00 00 00 10 00 00 00 10 00 00 00 10 00 00 00 00 00 00 00 10 00 00 00 40 00 00 00 20 00 00 00 08 00 00 00 02 00 00 00 00 00 00 00 06 00 00 00 12 00 00 00 22 00 00 00 36 00 00 00 4e 00 00 00 60 00 00 00 70 00 00 00 80 00 00 00 40 00 00 00 00 00 00 00 00 00 00 00 0c 00 00 00 22 00 00 00 37 00 00 00 4b 00 00 00 60 00 00 00 70 00 00 00 00 00 00 00 00 00 00 00 0c 04 00 00 02 00 00 00 08 00 00 00 90 01 00 00 90 01 00 00 00 00 00 00 20 03 00 00 20 03 00 00 20 03 00 00 ff 03 00 00 ff 03 00 00 02 00 00 00 02 00 00 00 01 00 00 00 02 00 00 00 02 00 00 00 02 00 00 00 02 00 00 00 02 00 00 00 06 00 00 00 06 00 00 00 06 00 00 00 06 00 00 00 06 00 00 00 07 00 00 00 07 00 00 00 08 00 00 00 80 00 00 00 05 00 00 00 c8 00 00 00 c8 00 00 00 c8 00 00 00 64 00 00 00 64 00 00 00 64 00 00 00 64 00 00 00 64 00 00 00 11 00 00 00 13 00 00 00 11 00 00 00 11 00 00 00 10 00 00 00 10 00 00 00 10 00 00 00 10 00 00 00 80 02 00 00 80 02 00 00 4e 02 00 00 1c 02 00 00 b8 01 00 00 b8 01 00 00 b8 01 00 00 b8 01 00 00 5f 00 00 00 5f 00 00 00 55 00 00 00 50 00 00 00 46 00 00 00 46 00 00 00 46 00 00 00 46 00 00 00 08 00 00 00 10 00 00 00 03 00 00 00 10 00 00 00 20 00 00 00 03 00 00 00 01 02 02 00 01 00 00 00 20 ff ff 40 04 02 40 04 02 00 00 00 46 00 00 00 55 00 00 00 64 00 00 00 73 00 00 00 80 00 00 00 40 00 00 00 e8 03 00 00 e8 03 00 00 20 00 00 00 20 00 00 00 20 00 00 00 20 00 00 00 10 00 00 00 10 00 00 00 10 00 00 00 10 00 00 00 10 00 00 00 10 00 00 00 10 00 00 00 10 00 00 00 00 00 00 00 10 00 00 00 40 00 00 00 20 00 00 00 08 00 00 00 02 00 00 00 00 00 00 00 06 00 00 00 12 00 00 00 22 00 00 00 36 00 00 00 4e 00 00 00 60 00 00 00 70 00 00 00 80 00 00 00 40 00 00 00 00 00 00 00 00 00 00 00 0c 00 00 00 22 00 00 00 37 00 00 00 4b 00 00 00 60 00 00 00 70 00 00 00 00 00 00 00 00 00 00 00 0c 04 00 00 02 00 00 00 08 00 00 00 90 01 00 00 90 01 00 00 00 00 00 00 20 03 00 00 20 03 00 00 20 03 00 00 ff 03 00 00 ff 03 00 00 02 00 00 00 02 00 00 00 01 00 00 00 02 00 00 00 02 00 00 00 02 00 00 00 02 00 00 00 02 00 00 00 06 00 00 00 06 00 00 00 06 00 00 00 06 00 00 00 06 00 00 00 07 00 00 00 07 00 00 00 08 00 00 00 80 00 00 00 05 00 00 00 c8 00 00 00 c8 00 00 00 c8 00 00 00 64 00 00 00 64 00 00 00 64 00 00 00 64 00 00 00 64 00 00 00 11 00 00 00 13 00 00 00 11 00 00 00 11 00 00 00 10 00 00 00 10 00 00 00 10 00 00 00 10 00 00 00 80 02 00 00 80 02 00 00 4e 02 00 00 1c 02 00 00 b8 01 00 00 b8 01 00 00 b8 01 00 00 b8 01 00 00 5f 00 00 00 5f 00 00 00 55 00 00 00 50 00 00 00 46 00 00 00 46 00 00 00 46 00 00 00 46 00 00 00 08 00 00 00 10 00 00 00 03 00 00 00 10 00 00 00 20 00 00 00 03 00 00 00 01 02 02 00 01 00 00 00 20 ff ff 40 04 02 40 04 02 00 00 00 46 00 00 00 55 00 00 00 64 00 00 00 73 00 00 00 80 00 00 00 40 00 00 00 e8 03 00 00 e8 03 00 00 20 00 00 00 20 00 00 00 20 00 00 00 20 00 00 00 10 00 00 00 10 00 00 00 10 00 00 00 10 00 00 00 10 00 00 00 10 00 00 00 10 00 00 00 10 00 00 00 00 00 00 00 10 00 00 00 40 00 00 00 20 00 00 00 08 00 00 00 02 00 00 00 00 00 00 00 06 00 00 00 12 00 00 00 22 00 00 00 36 00 00 00 4e 00 00 00 60 00 00 00 70 00 00 00 80 00 00 00 40 00 00 00 00 00 00 00 00 00 00 00 0c 00 00 00 22 00 00 00 37 00 00 00 4b 00 00 00 60 00 00 00 70 00 00 00 00 00 00 00 00 00 00 00 0c 04 00 00 02 00 00 00 08 00 00 00 90 01 00 00 90 01 00 00 00 00 00 00 20 03 00 00 20 03 00 00 20 03 00 00 ff 03 00 00 ff 03 00 00 02 00 00 00 02 00 00 00 01 00 00 00 02 00 00 00 02 00 00 00 02 00 00 00 02 00 00 00 02 00 00 00 06 00 00 00 06 00 00 00 06 00 00 00 06 00 00 00 06 00 00 00 07 00 00 00 07 00 00 00 08 00 00 00 80 00 00 00 05 00 00 00 c8 00 00 00 c8 00 00 00 c8 00 00 00 64 00 00 00 64 00 00 00 64 00 00 00 64 00 00 00 64 00 00 00 11 00 00 00 13 00 00 00 11 00 00 00 11 00 00 00 10 00 00 00 10 00 00 00 10 00 00 00 10 00 00 00 80 02 00 00 80 02 00 00 4e 02 00 00 1c 02 00 00 b8 01 00 00 b8 01 00 00 b8 01 00 00 b8 01 00 00 5f 00 00 00 5f 00 00 00 55 00 00 00 50 00 00 00 46 00 00 00 46 00 00 00 46 00 00 00 46 00 00 00 08 00 00 00 10 00 00 00 03 00 00 00 10 00 00 00 20 00 00 00 03 00 00 00 01 02 02 00 01 00 00 00 20 ff ff 40 04 02 40 04 02 00 00 00 46 00 00 00 55 00 00 00 64 00 00 00 73 00 00 00 80 00 00 00 40 00 00 00 e8 03 00 00 e8 03 00 00 20 00 00 00 20 00 00 00 20 00 00 00 20 00 00 00 10 00 00 00 10 00 00 00 10 00 00 00 10 00 00 00 10 00 00 00 10 00 00 00 10 00 00 00 10 00 00 00 00 00 00 00 10 00 00 00 40 00 00 00 20 00 00 00 08 00 00 00 02 00 00 00 00 00 00 00 06 00 00 00 12 00 00 00 22 00 00 00 36 00 00 00 4e 00 00 00 60 00 00 00 70 00 00 00 80 00 00 00 40 00 00 00 00 00 00 00 00 00 00 00 0c 00 00 00 22 00 00 00 37 00 00 00 4b 00 00 00 60 00 00 00 70 00 00 00 00 00 00 00 00 00 00 00 0c 04 00 00 02 00 00 00 08 00 00 00 90 01 00 00 90 01 00 00 00 00 00 00 20 03 00 00 20 03 00 00 20 03 00 00 ff 03 00 00 ff 03 00 00 02 00 00 00 02 00 00 00 01 00 00 00 02 00 00 00 02 00 00 00 02 00 00 00 02 00 00 00 02 00 00 00 06 00 00 00 06 00 00 00 06 00 00 00 06 00 00 00 06 00 00 00 07 00 00 00 07 00 00 00 08 00 00 00 80 00 00 00 05 00 00 00 c8 00 00 00 c8 00 00 00 c8 00 00 00 64 00 00 00 64 00 00 00 64 00 00 00 64 00 00 00 64 00 00 00 11 00 00 00 13 00 00 00 11 00 00 00 11 00 00 00 10 00 00 00 10 00 00 00 10 00 00 00 10 00 00 00 80 02 00 00 80 02 00 00 4e 02 00 00 1c 02 00 00 b8 01 00 00 b8 01 00 00 b8 01 00 00 b8 01 00 00 5f 00 00 00 5f 00 00 00 55 00 00 00 50 00 00 00 46 00 00 00 46 00 00 00 46 00 00 00 46 00 00 00 08 00 00 00 10 00 00 00 03 00 00 00 10 00 00 00 20 00 00 00 03 00 00 00 01 02 02 00 01 00 00 00 20 ff ff 40 04 02 40 04 02 00 00 00 46 00 00 00 55 00 00 00 64 00 00 00 73 00 00 00 80 00 00 00 40 00 00 00 e8 03 00 00 e8 03 00 00 20 00 00 00 20 00 00 00 20 00 00 00 20 00 00 00 10 00 00 00 10 00 00 00 10 00 00 00 10 00 00 00 10 00 00 00 10 00 00 00 10 00 00 00 10 00 00 00 00 00 00 00 10 00 00 00 40 00 00 00 20 00 00 00 08 00 00 00 02 00 00 00 00 00 00 00 06 00 00 00 12 00 00 00 22 00 00 00 36 00 00 00 4e 00 00 00 60 00 00 00 70 00 00 00 80 00 00 00 40 00 00 00 00 00 00 00 00 00 00 00 0c 00 00 00 22 00 00 00 37 00 00 00 4b 00 00 00 60 00 00 00 70 00 00 00 00 00 00 00 00 00 00 00 0c 04 00 00 02 00 00 00 08 00 00 00 90 01 00 00 90 01 00 00 00 00 00 00 20 03 00 00 20 03 00 00 20 03 00 00 ff 03 00 00 ff 03 00 00 02 00 00 00 02 00 00 00 01 00 00 00 02 00 00 00 02 00 00 00 02 00 00 00 02 00 00 00 02 00 00 00 06 00 00 00 06 00 00 00 06 00 00 00 06 00 00 00 06 00 00 00 07 00 00 00 07 00 00 00 08 00 00 00 80 00 00 00 05 00 00 00 c8 00 00 00 c8 00 00 00 c8 00 00 00 64 00 00 00 64 00 00 00 64 00 00 00 64 00 00 00 64 00 00 00 11 00 00 00 13 00 00 00 11 00 00 00 11 00 00 00 10 00 00 00 10 00 00 00 10 00 00 00 10 00 00 00 80 02 00 00 80 02 00 00 4e 02 00 00 1c 02 00 00 b8 01 00 00 b8 01 00 00 b8 01 00 00 b8 01 00 00 5f 00 00 00 5f 00 00 00 55 00 00 00 50 00 00 00 46 00 00 00 46 00 00 00 46 00 00 00 46 00 00 00 08 00 00 00 10 00 00 00 03 00 00 00 10 00 00 00 20 00 00 00 03 00 00 00 01 02 02 00 01 00 00 00 20 ff ff 40 04 02 40 04 02 00 00 00 46 00 00 00 55 00 00 00 64 00 00 00 73 00 00 00 80 00 00 00 40 00 00 00 e8 03 00 00 e8 03 00 00 20 00 00 00 20 00 00 00 20 00 00 00 20 00 00 00 10 00 00 00 10 00 00 00 10 00 00 00 10 00 00 00 10 00 00 00 10 00 00 00 10 00 00 00 10 00 00 00 00 00 00 00 10 00 00 00 40 00 00 00 20 00 00 00 08 00 00 00 02 00 00 00 00 00 00 00 06 00 00 00 12 00 00 00 22 00 00 00 36 00 00 00 4e 00 00 00 60 00 00 00 70 00 00 00 80 00 00 00 40 00 00 00 00 00 00 00 00 00 00 00 0c 00 00 00 22 00 00 00 37 00 00 00 4b 00 00 00 60 00 00 00 70 00 00 00 00 00 00 00 00 00 00 00 0c 04 00 00];
		};
		iq_wdr {
			size = [e4 02 00 00];
			data = [01 00 00 00 00 00 00 00 20 00 00 00 12 00 00 00 ff 00 00 00 05 00 00 00 03 00 00 00 00 00 00 00 01 00 00 00 02 00 00 00 03 00 00 00 04 00 00 00 05 00 00 00 07 00 00 00 0b 00 00 00 13 00 00 00 1b 00 00 00 23 00 00 00 27 00 00 00 2b 00 00 00 2d 00 00 00 2e 00 00 00 2f 00 00 00 30 00 00 00 31 00 00 00 32 00 00 00 33 00 00 00 34 00 00 00 35 00 00 00 36 00 00 00 37 00 00 00 38 00 00 00 39 00 00 00 3a 00 00 00 3b 00 00 00 3c 00 00 00 3d 00 00 00 3e 00 00 00 3f 00 00 00 00 00 00 00 00 00 00 00 00 00 00 00 00 00 00 00 00 00 00 00 01 00 00 00 02 00 00 00 03 00 00 00 03 00 00 00 03 00 00 00 02 00 00 00 02 00 00 00 01 00 00 00 00 00 00 00 00 00 00 00 00 00 00 00 00 00 00 00 00 00 00 00 00 00 00 00 00 00 00 00 00 00 00 00 00 00 00 00 00 00 00 00 00 00 00 00 00 00 00 00 00 00 00 00 00 00 00 00 00 00 00 00 00 00 00 00 00 00 00 00 00 00 00 00 00 00 00 00 ff 0f 00 00 ff 0f 00 00 fe 0f 00 00 f4 0f 00 00 d0 0f 00 00 73 0f 00 00 23 0f 00 00 b6 0e 00 00 74 0e 00 00 29 0e 00 00 d7 0d 00 00 7c 0d 00 00 4c 0d 00 00 1b 0d 00 00 e7 0c 00 00 b2 0c 00 00 7b 0c 00 00 43 0c 00 00 0a 0c 00 00 cf 0b 00 00 93 0b 00 00 57 0b 00 00 1a 0b 00 00 dc 0a 00 00 9e 0a 00 00 60 0a 00 00 22 0a 00 00 e4 09 00 00 a6 09 00 00 68 09 00 00 2b 09 00 00 ee 08 00 00 b2 08 00 00 77 08 00 00 3d 08 00 00 04 08 00 00 95 07 00 00 2b 07 00 00 c6 06 00 00 67 06 00 00 0d 06 00 00 b9 05 00 00 6a 05 00 00 21 05 00 00 9e 04 00 00 2d 04 00 00 7d 03 00 00 fe 02 00 00 a3 02 00 00 62 02 00 00 32 02 00 00 0f 02 00 00 f5 01 00 00 e2 01 00 00 d3 01 00 00 c8 01 00 00 bf 01 00 00 b8 01 00 00 b3 01 00 00 ae 01 00 00 ab 01 00 00 a8 01 00 00 a6 01 00 00 a4 01 00 00 a2 01 00 00 20 00 00 00 80 00 00 00 00 00 00 00 ff 00 00 00 80 00 00 00 00 00 00 00 ff 00 00 00 60 00 00 00 00 00 00 00 ff 00 00 00 60 00 00 00 00 00 00 00 ff 00 00 00 50 00 00 00 00 00 00 00 ff 00 00 00 50 00 00 00 00 00 00 00 ff 00 00 00 40 00 00 00 00 00 00 00 80 00 00 00 30 00 00 00 00 00 00 00 40 00 00 00 30 00 00 00 00 00 00 00 30 00 00 00 30 00 00 00 00 00 00 00 30 00 00 00 30 00 00 00 00 00 00 00 30 00 00 00 30 00 00 00 00 00 00 00 30 00 00 00 30 00 00 00 00 00 00 00 30 00 00 00 30 00 00 00 00 00 00 00 30 00 00 00 30 00 00 00 00 00 00 00 30 00 00 00 30 00 00 00 00 00 00 00 30 00 00 00];
		};
		iq_shdr {
			size = [ec 01 00 00];
			data = [01 00 00 00 00 00 00 00 01 00 00 00 00 0c 09 00 c0 00 06 00 01 00 00 00 00 0c 09 00 c0 00 06 00 02 00 00 02 04 08 0a 0c 0e 10 0e 0c 0a 08 06 04 02 00 00 00 00 00 00 00 04 00 08 10 18 1c 20 24 26 28 29 2a 2b 2c 2d 2e 2f 30 31 32 33 34 35 36 37 38 39 3a 3b 3c 3d 3e 3f 03 03 03 02 02 02 01 01 00 00 00 00 00 00 00 00 00 00 00 00 00 00 00 00 00 00 00 00 00 00 00 00 00 00 00 75 00 e0 00 43 01 9e 01 f3 01 43 02 8e 02 d5 02 18 03 58 03 95 03 cf 03 06 04 3b 04 6e 04 94 04 b4 04 ca 04 e0 04 f5 04 0a 05 1e 05 32 05 46 05 6c 05 92 05 b6 05 d9 05 fc 05 1d 06 3e 06 5f 06 7e 06 9d 06 bc 06 da 06 15 07 4f 07 87 07 be 07 29 08 8f 08 f3 08 55 09 b4 09 12 0a 6e 0a c8 0a 21 0b 79 0b d1 0b 27 0c 7c 0c d1 0c 24 0d 78 0d ca 0d 1d 0e 6e 0e bf 0e 10 0f 60 0f b0 0f ff 0f e0 00 04 05 06 07 08 08 00 00 01 02 03 00 00 00 00 00 00 00 00 00 00 00 00 00 00 00 00 00 00 00 00 00 00 00 00 00 00 00 00 00 00 00 00 00 00 00 00 00 00 00 00 00 00 00 00 00 00 00 00 00 00 00 00 00 00 00 00 00 00 00 00 00 00 00 00 00 00 00 00 00 00 00 10 00 02 03 04 05 06 06 00 01 02 03 03 00 40 00 64 82 a0 be dc dc 01 02 03 03 03 00 e0 00 04 05 06 07 08 08 00 00 01 02 03 00 e0 00 04 05 06 07 08 08 00 00 01 02 03 00 e0 00 04 05 06 07 08 08 00 00 01 02 03 00 e0 00 04 05 06 07 08 08 00 00 01 02 03 00 e0 00 04 05 06 07 08 08 00 00 01 02 03 00 e0 00 04 05 06 07 08 08 00 00 01 02 03 00 e0 00 04 05 06 07 08 08 00 00 01 02 03 00 e0 00 04 05 06 07 08 08 00 00 01 02 03 00 e0 00 04 05 06 07 08 08 00 00 01 02 03 00 00 00];
		};
		iq_rgbir {
			size = [28 00 00 00];
			data = [00 00 00 00 cc 00 00 00 cc 00 00 00 e6 00 00 00 00 01 00 00 cc 00 00 00 cc 00 00 00 e6 00 00 00 dc 00 00 00 f0 00 00 00];
		};
		iq_companding {
			size = [18 01 00 00];
			data = [00 02 00 00 00 03 00 00 00 0a 00 00 ff 0f 00 00 ff 0f 00 00 ff 0f 00 00 ff 0f 00 00 ff 0f 00 00 ff 0f 00 00 ff 0f 00 00 ff 0f 00 00 00 00 00 00 00 01 00 00 00 02 00 00 00 08 00 00 00 08 00 00 00 08 00 00 00 08 00 00 00 08 00 00 00 08 00 00 00 08 00 00 00 08 00 00 00 08 00 00 04 00 00 00 05 00 00 00 06 00 00 00 08 00 00 00 08 00 00 00 08 00 00 00 08 00 00 00 08 00 00 00 08 00 00 00 08 00 00 00 08 00 00 00 08 00 00 00 0a 00 00 00 0b 00 00 00 0c 00 00 00 0d 00 00 00 0e 00 00 00 0f 00 00 00 10 00 00 00 10 00 00 00 10 00 00 00 10 00 00 00 10 00 00 00 00 00 00 00 00 02 00 00 00 04 00 00 00 06 00 00 00 08 00 00 00 0a 00 00 00 0c 00 00 00 0c 00 00 00 0c 00 00 00 0c 00 00 00 0c 00 00 00 0c 00 00 03 00 00 00 04 00 00 00 05 00 00 00 06 00 00 00 07 00 00 00 08 00 00 00 09 00 00 00 09 00 00 00 09 00 00 00 09 00 00 00 09 00 00 00 09 00 00 00];
		};
		iq_rgbir_enh {
			size = [18 01 00 00];
			data = [01 00 00 00 00 00 00 00 32 00 00 00 10 00 00 00 10 00 00 00 10 00 00 00 10 00 00 00 10 00 00 00 10 00 00 00 10 00 00 00 10 00 00 00 10 00 00 00 10 00 00 00 10 00 00 00 10 00 00 00 10 00 00 00 10 00 00 00 10 00 00 00 10 00 00 00 80 00 00 00 20 00 00 00 20 00 00 00 20 00 00 00 20 00 00 00 20 00 00 00 20 00 00 00 20 00 00 00 20 00 00 00 20 00 00 00 20 00 00 00 20 00 00 00 20 00 00 00 20 00 00 00 20 00 00 00 20 00 00 00 20 00 00 00 98 00 00 00 50 00 00 00 50 00 00 00 50 00 00 00 50 00 00 00 50 00 00 00 50 00 00 00 50 00 00 00 50 00 00 00 50 00 00 00 50 00 00 00 50 00 00 00 50 00 00 00 50 00 00 00 50 00 00 00 50 00 00 00 50 00 00 00 ff 00 00 00 a0 00 00 00 a0 00 00 00 a0 00 00 00 a0 00 00 00 a0 00 00 00 a0 00 00 00 a0 00 00 00 a0 00 00 00 a0 00 00 00 a0 00 00 00 a0 00 00 00 a0 00 00 00 a0 00 00 00 a0 00 00 00 a0 00 00 00 a0 00 00 00];
		};
		iq_post_sharpen {
			size = [4c 02 00 00];
			data = [01 00 00 00 00 00 00 00 69 23 23 23 23 23 23 23 23 23 23 23 23 23 23 23 23 23 02 ff fa 00 5e 01 50 50 50 80 ff 00 40 80 80 00 19 23 23 23 23 23 23 23 23 23 23 23 23 23 23 23 23 23 02 ff 96 00 fa 00 50 50 50 80 ff 00 40 80 80 00 19 23 23 23 23 23 23 23 23 23 23 23 23 23 23 23 23 23 02 ff 96 00 fa 00 50 50 50 80 ff 00 40 80 80 00 19 23 23 23 23 23 23 23 23 23 23 23 23 23 23 23 23 23 02 ff 96 00 fa 00 50 50 50 80 ff 00 40 80 80 00 19 23 23 23 23 23 23 23 23 23 23 23 23 23 23 23 23 23 02 ff 96 00 fa 00 50 50 50 80 ff 00 40 80 80 00 19 23 23 23 23 23 23 23 23 23 23 23 23 23 23 23 23 23 02 ff 96 00 fa 00 50 50 50 80 ff 00 40 80 80 00 19 23 23 23 23 23 23 23 23 23 23 23 23 23 23 23 23 23 02 ff 96 00 fa 00 50 50 50 80 ff 00 40 80 80 00 19 23 23 23 23 23 23 23 23 23 23 23 23 23 23 23 23 23 02 ff 96 00 fa 00 50 50 50 80 ff 00 40 80 80 00 19 23 23 23 23 23 23 23 23 23 23 23 23 23 23 23 23 23 02 ff 96 00 fa 00 50 50 50 80 ff 00 40 80 80 00 19 23 23 23 23 23 23 23 23 23 23 23 23 23 23 23 23 23 02 ff 64 00 c8 00 50 50 50 80 ff 00 40 80 80 00 19 23 23 23 23 23 23 23 23 23 23 23 23 23 23 23 23 23 02 ff 64 00 c8 00 50 50 50 80 ff 00 40 80 80 00 69 23 23 23 23 23 23 23 23 23 23 23 23 23 23 23 23 23 02 ff 64 00 c8 00 50 50 50 80 ff 00 40 80 80 00 69 23 23 23 23 23 23 23 23 23 23 23 23 23 23 23 23 23 02 ff 64 00 c8 00 50 50 50 80 ff 00 40 80 80 00 69 23 23 23 23 23 23 23 23 23 23 23 23 23 23 23 23 23 02 ff 64 00 c8 00 50 50 50 80 ff 00 40 80 80 00 69 23 23 23 23 23 23 23 23 23 23 23 23 23 23 23 23 23 02 ff 64 00 c8 00 50 50 50 80 ff 00 40 80 80 00 69 23 23 23 23 23 23 23 23 23 23 23 23 23 23 23 23 23 02 ff 64 00 c8 00 50 50 50 80 ff 00 40 80 80 00 69 23 23 23 23 23 23 23 23 23 23 23 23 23 23 23 23 23 02 ff 64 00 c8 00 50 50 50 80 ff 00 40 80 80 00 00 00];
		};
		iq_ycurve {
			size = [08 02 00 00];
			data = [00 00 00 00 00 00 00 00 02 00 00 00 04 00 00 00 06 00 00 00 08 00 00 00 0a 00 00 00 0c 00 00 00 0e 00 00 00 10 00 00 00 12 00 00 00 14 00 00 00 16 00 00 00 18 00 00 00 1a 00 00 00 1c 00 00 00 1e 00 00 00 20 00 00 00 22 00 00 00 24 00 00 00 26 00 00 00 28 00 00 00 2a 00 00 00 2c 00 00 00 2e 00 00 00 30 00 00 00 32 00 00 00 34 00 00 00 36 00 00 00 38 00 00 00 3a 00 00 00 3c 00 00 00 3e 00 00 00 40 00 00 00 42 00 00 00 44 00 00 00 46 00 00 00 48 00 00 00 4a 00 00 00 4c 00 00 00 4e 00 00 00 50 00 00 00 52 00 00 00 54 00 00 00 56 00 00 00 58 00 00 00 5a 00 00 00 5c 00 00 00 5d 00 00 00 5f 00 00 00 61 00 00 00 64 00 00 00 66 00 00 00 68 00 00 00 6a 00 00 00 6c 00 00 00 6e 00 00 00 70 00 00 00 72 00 00 00 74 00 00 00 76 00 00 00 78 00 00 00 7a 00 00 00 7c 00 00 00 7e 00 00 00 80 00 00 00 82 00 00 00 84 00 00 00 86 00 00 00 88 00 00 00 8a 00 00 00 8c 00 00 00 8e 00 00 00 90 00 00 00 92 00 00 00 94 00 00 00 96 00 00 00 98 00 00 00 9a 00 00 00 9c 00 00 00 9e 00 00 00 a0 00 00 00 a2 00 00 00 a4 00 00 00 a6 00 00 00 a8 00 00 00 aa 00 00 00 ac 00 00 00 ae 00 00 00 b0 00 00 00 b2 00 00 00 b4 00 00 00 b6 00 00 00 b8 00 00 00 ba 00 00 00 bc 00 00 00 be 00 00 00 c0 00 00 00 c2 00 00 00 c4 00 00 00 c6 00 00 00 c8 00 00 00 ca 00 00 00 cc 00 00 00 ce 00 00 00 d0 00 00 00 d2 00 00 00 d4 00 00 00 d6 00 00 00 d8 00 00 00 da 00 00 00 dc 00 00 00 de 00 00 00 e0 00 00 00 e2 00 00 00 e4 00 00 00 e6 00 00 00 e8 00 00 00 ea 00 00 00 ec 00 00 00 ee 00 00 00 f0 00 00 00 f2 00 00 00 f4 00 00 00 f6 00 00 00 f8 00 00 00 fa 00 00 00 fc 00 00 00 fe 00 00 00 ff 00 00 00];
		};
		iq_shdr_ext {
			size = [11 00 00 00];
			data = [ff ff ff ff ff ff ff ff ff ff ff ff ff ff ff ff ff];
		};
		iq_cst {
			size = [16 00 00 00];
			data = [4d 00 96 00 1d 00 d5 ff ab ff 80 00 80 00 95 ff eb ff 00 00 80 80];
		};
	};
};
